VERSION ""

NS_ :

BS_:

BU_: TLM TLM ECU HV TLM TLM HV TLM ECU STEERING_WHEEL HV ECU TLM INVERTER_L HV INVERTER_L TLM ECU ECU INVERTER_L LV ECU HV TLM LV TLM TLM STEERING_WHEEL LV HV LV HV LV HV LV TLM TLM LV HV ECU LV TLM HANDCART HV ECU HV HANDCART HV HV ECU HV ECU HV HV TLM HV CHARGER TLM HV HANDCART HV HANDCART HV HV CHARGER CHARGER ECU LV HANDCART STEERING_WHEEL TLM HANDCART TLM TLM CHARGER HV ECU HANDCART ECU TLM HANDCART HANDCART ECU STEERING_WHEEL HANDCART ECU HV HV ANY LV HV LV ANY ECU ECU ANY LV HV ANY LV ANY HANDCART ECU HV ANY STEERING_WHEEL LV HANDCART CHARGER HANDCART LV LV CHARGER STEERING_WHEEL HANDCART LV STEERING_WHEEL HANDCART CHARGER LV CHARGER ECU TLM LV HANDCART TLM TLM HV CHARGER LV HV LV HANDCART LV TLM TLM CHARGER ECU HV ECU HANDCART LV TLM ECU CHARGER ECU HV HV HANDCART ECU TLM LV HV CHARGER ECU HANDCART LV CHARGER ECU HANDCART TLM LV STEERING_WHEEL LV LV ECU ECU HANDCART LV ECU HV TLM HV HANDCART HANDCART HV HV HANDCART STEERING_WHEEL HANDCART HV TLM TLM ECU HANDCART HANDCART ECU ECU STEERING_WHEEL ECU HV ECU STEERING_WHEEL HANDCART CHARGER ECU TLM HANDCART ECU HANDCART ECU STEERING_WHEEL CHARGER ECU HANDCART STEERING_WHEEL CHARGER ECU HV HANDCART ECU ECU CHARGER STEERING_WHEEL CHARGER ECU HANDCART ECU TLM CHARGER INVERTER_L TLM

BO_ 1818 NLG5_DIAG_TX: 8 NLG5
 SG_ LAD_D_ParamRp : 7|64@0+ (1,0) [0|0] "" Vector__XXX

BO_ 1816 NLG5_DIAG_RX: 8 Control
 SG_ LAD_D_ParamRq : 7|64@0+ (1,0) [0|0] "" Vector__XXX

BO_ 1556 NLG5_ERR: 5 NLG5
 SG_ NLG5_W_SC_M : 32|1@0+ (1,0) [0|0] ""  Control
 SG_ NLG5_W_OD : 33|1@0+ (1,0) [0|0] "" Vector__XXX
 SG_ NLG5_W_CM_NA : 35|1@0+ (1,0) [0|0] "" Vector__XXX
 SG_ NLG5_W_C_VOR : 36|1@0+ (1,0) [0|1] ""  Control
 SG_ NLG5_W_PL_IT : 37|1@0+ (1,0) [0|1] ""  Control
 SG_ NLG5_W_PL_BV : 38|1@0+ (1,0) [0|1] ""  Control
 SG_ NLG5_W_PL_MV : 39|1@0+ (1,0) [0|1] ""  Control
 SG_ NLG5_E_SDT_CT : 26|1@0+ (1,0) [0|1] ""  Control
 SG_ NLG5_E_SDT_AH : 27|1@0+ (1,0) [0|1] ""  Control
 SG_ NLG5_E_SDT_BV : 28|1@0+ (1,0) [0|1] ""  Control
 SG_ NLG5_E_SDT_BT : 29|1@0+ (1,0) [0|1] ""  Control
 SG_ NLG5_E_C_RX : 30|1@0+ (1,0) [0|1] ""  Control
 SG_ NLG5_E_C_TX : 31|1@0+ (1,0) [0|1] ""  Control
 SG_ NLG5_E_C_OFF : 16|1@0+ (1,0) [0|1] ""  Control
 SG_ NLG5_E_C_TO : 17|1@0+ (1,0) [0|1] ""  Control
 SG_ NLG5_E_INIT : 18|1@0+ (1,0) [0|1] ""  Control
 SG_ NLG5_E_WDT : 19|1@0+ (1,0) [0|1] ""  Control
 SG_ NLG5_E_EP_CRC : 20|1@0+ (1,0) [0|1] ""  Control
 SG_ NLG5_E_ES_CRC : 21|1@0+ (1,0) [0|1] ""  Control
 SG_ NLG5_E_NV_CRC : 22|1@0+ (1,0) [0|1] ""  Control
 SG_ NLG5_E_F_CRC : 23|1@0+ (1,0) [0|1] ""  Control
 SG_ NLG5_E_T_EXT3 : 8|1@0+ (1,0) [0|1] ""  Control
 SG_ NLG5_E_T_EXT2 : 9|1@0+ (1,0) [0|1] ""  Control
 SG_ NLG5_E_T_EXT1 : 10|1@0+ (1,0) [0|1] ""  Control
 SG_ NLG5_E_T_TR : 11|1@0+ (1,0) [0|1] ""  Control
 SG_ NLG5_E_T_DIO : 12|1@0+ (1,0) [0|1] ""  Control
 SG_ NLG5_E_T_POW : 13|1@0+ (1,0) [0|1] ""  Control
 SG_ NLG5_E_T_C : 14|1@0+ (1,0) [0|1] ""  Control
 SG_ NLG5_E_B_P : 15|1@0+ (1,0) [0|1] ""  Control
 SG_ NLG5_E_MF : 0|1@0+ (1,0) [0|1] ""  Control
 SG_ NLG5_E_OF : 1|1@0+ (1,0) [0|1] ""  Control
 SG_ NLG5_E_P_MV : 2|1@0+ (1,0) [0|1] ""  Control
 SG_ NLG5_E_P_OM : 3|1@0+ (1,0) [0|1] ""  Control
 SG_ NLG5_E_SC : 4|1@0+ (1,0) [0|1] ""  Control
 SG_ NLG5_E_MOV_I : 5|1@0+ (1,0) [0|1] ""  Control
 SG_ NLG5_E_MOV_II : 6|1@0+ (1,0) [0|1] ""  Control
 SG_ NLG5_E_OOV : 7|1@0+ (1,0) [0|1] ""  Control

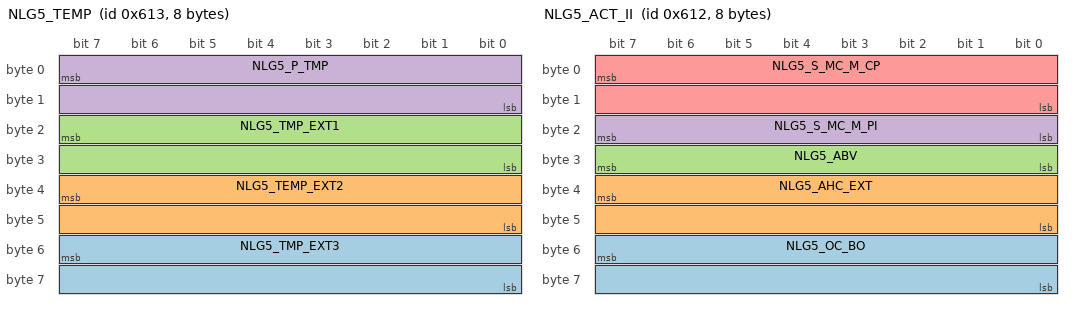
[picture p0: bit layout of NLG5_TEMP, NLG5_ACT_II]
BO_ 1555 NLG5_TEMP: 8 NLG5
 SG_ NLG5_TMP_EXT3 : 55|16@0- (0.1,0) [-40|300] "°C"  Control
 SG_ NLG5_TEMP_EXT2 : 39|16@0- (0.1,0) [-40|300] "°C"  Control
 SG_ NLG5_TMP_EXT1 : 23|16@0- (0.1,0) [-40|300] "°C"  Control
 SG_ NLG5_P_TMP : 7|16@0- (0.1,0) [-40|300] "°C"  Control

BO_ 1554 NLG5_ACT_II: 8 NLG5
 SG_ NLG5_OC_BO : 55|16@0+ (0.01,0) [0|50] "A"  Control
 SG_ NLG5_AHC_EXT : 39|16@0- (0.01,0) [-327.68|327.67] "Ah"  Control
 SG_ NLG5_ABV : 31|8@0+ (0.1,0) [0|25] "V"  Control
 SG_ NLG5_S_MC_M_PI : 23|8@0+ (0.1,0) [0|20] "A"  Control
 SG_ NLG5_S_MC_M_CP : 7|16@0+ (0.1,0) [0|100] "A"  Control

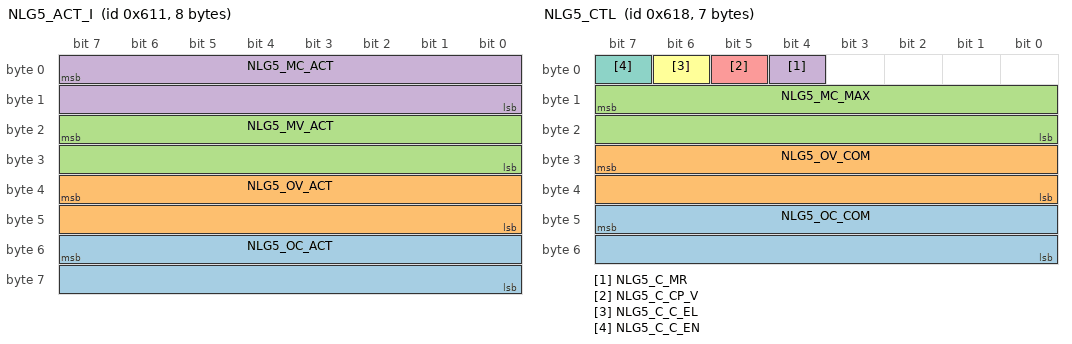
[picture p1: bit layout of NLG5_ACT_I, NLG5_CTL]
BO_ 1553 NLG5_ACT_I: 8 NLG5
 SG_ NLG5_OC_ACT : 55|16@0- (0.01,0) [0|150] "A"  Control
 SG_ NLG5_OV_ACT : 39|16@0+ (0.1,0) [0|1000] "V"  Control
 SG_ NLG5_MV_ACT : 23|16@0+ (0.1,0) [0|500] "V"  Control
 SG_ NLG5_MC_ACT : 7|16@0+ (0.01,0) [0|50] "A"  Control

BO_ 1552 NLG5_ST: 4 NLG5
 SG_ NLG5_S_AAC : 24|1@0+ (1,0) [0|1] ""  Control
 SG_ NLG5_S_L_T_BATT : 16|1@0+ (1,0) [0|1] ""  Control
 SG_ NLG5_S_L_T_TR : 17|1@0+ (1,0) [0|1] ""  Control
 SG_ NLG5_S_L_T_DIO : 18|1@0+ (1,0) [0|1] ""  Control
 SG_ NLG5_S_L_T_POW : 19|1@0+ (1,0) [0|1] ""  Control
 SG_ NLG5_S_L_T_CPRIM : 20|1@0+ (1,0) [0|1] ""  Control
 SG_ NLG5_S_L_MO_MAX : 21|1@0+ (1,0) [0|1] ""  Control
 SG_ NLG5_S_L_OC_MAX : 22|1@0+ (1,0) [0|1] ""  Control
 SG_ NLG5_S_L_MC_MAX : 23|1@0+ (1,0) [0|1] ""  Control
 SG_ NLG5_S_L_PMAX : 8|1@0+ (1,0) [0|1] ""  Control
 SG_ NLG5_S_L_CP : 9|1@0+ (1,0) [0|1] ""  Control
 SG_ NLG5_S_L_PI : 10|1@0+ (1,0) [0|1] ""  Control
 SG_ NLG5_S_L_MC : 11|1@0+ (1,0) [0|1] ""  Control
 SG_ NLG5_S_L_OC : 12|1@0+ (1,0) [0|1] ""  Control
 SG_ NLG5_S_L_OV : 13|1@0+ (1,0) [0|1] ""  Control
 SG_ NLG5_S_BPD_II : 14|1@0+ (1,0) [0|1] ""  Control
 SG_ NLG5_S_BPD_I : 15|1@0+ (1,0) [0|1] ""  Control
 SG_ NLG5_S_CP_DT : 0|1@0+ (1,0) [0|1] ""  Control
 SG_ NLG5_S_UM_II : 1|1@0+ (1,0) [0|1] ""  Control
 SG_ NLG5_S_UM_I : 2|1@0+ (1,0) [0|1] ""  Control
 SG_ NLG5_S_EUM : 3|1@0+ (1,0) [0|1] ""  Control
 SG_ NLG5_S_FAN : 4|1@0+ (1,0) [0|1] ""  Control
 SG_ NLG5_S_WAR : 5|1@0+ (1,0) [0|1] ""  Control
 SG_ NLG5_S_ERR : 6|1@0+ (1,0) [0|1] ""  Control
 SG_ NLG5_S_HE : 7|1@0+ (1,0) [0|1] ""  Control

BO_ 1560 NLG5_CTL: 7 Control
 SG_ NLG5_OC_COM : 47|16@0+ (0.1,0) [0|150] "A"  NLG5
 SG_ NLG5_OV_COM : 31|16@0+ (0.1,0) [0|1000] "V"  NLG5
 SG_ NLG5_MC_MAX : 15|16@0+ (0.1,0) [0|50] "A"  NLG5
 SG_ NLG5_C_MR : 4|1@0+ (1,0) [0|1] ""  NLG5
 SG_ NLG5_C_CP_V : 5|1@0+ (1,0) [0|1] ""  NLG5
 SG_ NLG5_C_C_EL : 6|1@0+ (1,0) [0|1] ""  NLG5
 SG_ NLG5_C_C_EN : 7|1@0+ (1,0) [0|1] ""  NLG5

BO_ 0 HV_JMP_TO_BLT: 1 Vector__XXX
 SG_ cellboard_id : 1|3@1+ (1,0) [0|7] "" Vector__XXX
 SG_ forward : 0|1@1+ (1,0) [0|1] "" Vector__XXX

BO_ 1 HV_FLASH_MAINBOARD_TX: 0 Vector__XXX

BO_ 2 HV_FLASH_MAINBOARD_RX: 0 Vector__XXX

BO_ 4 HV_FLASH_CELLBOARD_0_TX: 0 Vector__XXX

BO_ 5 HV_FLASH_CELLBOARD_0_RX: 0 Vector__XXX

BO_ 6 HV_FLASH_CELLBOARD_1_TX: 0 Vector__XXX

BO_ 7 HV_FLASH_CELLBOARD_1_RX: 0 Vector__XXX

BO_ 8 HV_FLASH_CELLBOARD_2_TX: 0 Vector__XXX

BO_ 9 HV_FLASH_CELLBOARD_2_RX: 0 Vector__XXX

BO_ 10 HV_FLASH_CELLBOARD_3_TX: 0 Vector__XXX

BO_ 11 HV_FLASH_CELLBOARD_3_RX: 0 Vector__XXX

BO_ 12 HV_FLASH_CELLBOARD_4_TX: 0 Vector__XXX

BO_ 13 HV_FLASH_CELLBOARD_4_RX: 0 Vector__XXX

BO_ 14 HV_FLASH_CELLBOARD_5_TX: 0 Vector__XXX

BO_ 15 HV_FLASH_CELLBOARD_5_RX: 0 Vector__XXX

BO_ 16 LV_JMP_TO_BLT: 0 Vector__XXX

BO_ 17 LV_FLASH_TX: 0 Vector__XXX

BO_ 18 LV_FLASH_RX: 0 Vector__XXX

BO_ 19 ECU_JMP_TO_BLT: 0 Vector__XXX

BO_ 20 ECU_FLASH_TX: 0 Vector__XXX

BO_ 21 ECU_FLASH_RX: 0 Vector__XXX

BO_ 22 STEERING_WHEEL_JMP_TO_BLT: 0 Vector__XXX

BO_ 23 STEERING_WHEEL_FLASH_TX: 0 Vector__XXX

BO_ 24 STEERING_WHEEL_FLASH_RX: 0 Vector__XXX

BO_ 700 STEERING_WHEEL_VERSION: 8 Vector__XXX
 SG_ canlib_build_time : 32|32@1+ (1,0) [0|4294967295] "" Vector__XXX
 SG_ component_build_time : 0|32@1+ (1,0) [0|4294967295] "" Vector__XXX

BO_ 701 ECU_VERSION: 8 Vector__XXX
 SG_ canlib_build_time : 32|32@1+ (1,0) [0|4294967295] "" Vector__XXX
 SG_ component_build_time : 0|32@1+ (1,0) [0|4294967295] "" Vector__XXX

BO_ 703 LV_VERSION: 8 Vector__XXX
 SG_ canlib_build_time : 32|32@1+ (1,0) [0|4294967295] "" Vector__XXX
 SG_ component_build_time : 0|32@1+ (1,0) [0|4294967295] "" Vector__XXX

BO_ 704 TLM_VERSION: 8 Vector__XXX
 SG_ canlib_build_time : 32|32@1+ (1,0) [0|4294967295] "" Vector__XXX
 SG_ component_build_time : 0|32@1+ (1,0) [0|4294967295] "" Vector__XXX

BO_ 702 HV_MAINBOARD_VERSION: 8 Vector__XXX
 SG_ canlib_build_time : 32|32@1+ (1,0) [0|4294967295] "" Vector__XXX
 SG_ component_build_time : 0|32@1+ (1,0) [0|4294967295] "" Vector__XXX

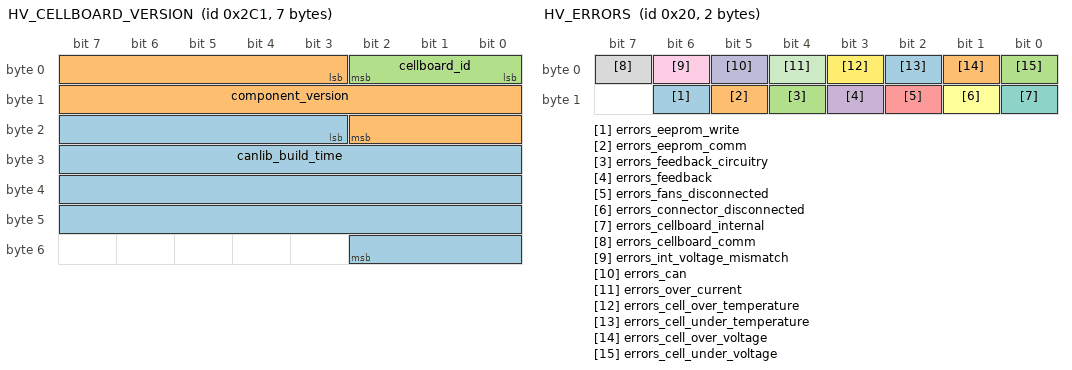
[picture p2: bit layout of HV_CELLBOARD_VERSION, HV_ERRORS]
BO_ 705 HV_CELLBOARD_VERSION: 7 Vector__XXX
 SG_ canlib_build_time : 19|32@1+ (1,0) [0|4294967295] "" Vector__XXX
 SG_ component_version : 3|16@1+ (1,0) [0|65535] "" Vector__XXX
 SG_ cellboard_id : 0|3@1+ (1,0) [0|7] "" Vector__XXX

BO_ 32 HV_ERRORS: 2 Vector__XXX
 SG_ errors_eeprom_write : 14|1@1+ (1,0) [0|1] "" Vector__XXX
 SG_ errors_eeprom_comm : 13|1@1+ (1,0) [0|1] "" Vector__XXX
 SG_ errors_feedback_circuitry : 12|1@1+ (1,0) [0|1] "" Vector__XXX
 SG_ errors_feedback : 11|1@1+ (1,0) [0|1] "" Vector__XXX
 SG_ errors_fans_disconnected : 10|1@1+ (1,0) [0|1] "" Vector__XXX
 SG_ errors_connector_disconnected : 9|1@1+ (1,0) [0|1] "" Vector__XXX
 SG_ errors_cellboard_internal : 8|1@1+ (1,0) [0|1] "" Vector__XXX
 SG_ errors_cellboard_comm : 7|1@1+ (1,0) [0|1] "" Vector__XXX
 SG_ errors_int_voltage_mismatch : 6|1@1+ (1,0) [0|1] "" Vector__XXX
 SG_ errors_can : 5|1@1+ (1,0) [0|1] "" Vector__XXX
 SG_ errors_over_current : 4|1@1+ (1,0) [0|1] "" Vector__XXX
 SG_ errors_cell_over_temperature : 3|1@1+ (1,0) [0|1] "" Vector__XXX
 SG_ errors_cell_under_temperature : 2|1@1+ (1,0) [0|1] "" Vector__XXX
 SG_ errors_cell_over_voltage : 1|1@1+ (1,0) [0|1] "" Vector__XXX
 SG_ errors_cell_under_voltage : 0|1@1+ (1,0) [0|1] "" Vector__XXX

BO_ 512 HV_DEBUG_SIGNALS: 5 Vector__XXX
 SG_ errors_eeprom_write : 34|1@1+ (1,0) [0|1] "" Vector__XXX
 SG_ errors_eeprom_comm : 33|1@1+ (1,0) [0|1] "" Vector__XXX
 SG_ errors_feedback_circuitry : 32|1@1+ (1,0) [0|1] "" Vector__XXX
 SG_ errors_feedback : 31|1@1+ (1,0) [0|1] "" Vector__XXX
 SG_ errors_fans_disconnected : 30|1@1+ (1,0) [0|1] "" Vector__XXX
 SG_ errors_connector_disconnected : 29|1@1+ (1,0) [0|1] "" Vector__XXX
 SG_ errors_cellboard_internal : 28|1@1+ (1,0) [0|1] "" Vector__XXX
 SG_ errors_cellboard_comm : 27|1@1+ (1,0) [0|1] "" Vector__XXX
 SG_ errors_int_voltage_mismatch : 26|1@1+ (1,0) [0|1] "" Vector__XXX
 SG_ errors_can : 25|1@1+ (1,0) [0|1] "" Vector__XXX
 SG_ errors_over_current : 24|1@1+ (1,0) [0|1] "" Vector__XXX
 SG_ errors_cell_over_temperature : 23|1@1+ (1,0) [0|1] "" Vector__XXX
 SG_ errors_cell_under_temperature : 22|1@1+ (1,0) [0|1] "" Vector__XXX
 SG_ errors_cell_over_voltage : 21|1@1+ (1,0) [0|1] "" Vector__XXX
 SG_ errors_cell_under_voltage : 20|1@1+ (1,0) [0|1] "" Vector__XXX
 SG_ feedbacks_sd_imd : 19|1@1+ (1,0) [0|1] "" Vector__XXX
 SG_ feedbacks_sd_bms : 18|1@1+ (1,0) [0|1] "" Vector__XXX
 SG_ feedbacks_sd_in : 17|1@1+ (1,0) [0|1] "" Vector__XXX
 SG_ feedbacks_sd_out : 16|1@1+ (1,0) [0|1] "" Vector__XXX
 SG_ feedbacks_sd_end : 15|1@1+ (1,0) [0|1] "" Vector__XXX
 SG_ feedbacks_check_mux : 14|1@1+ (1,0) [0|1] "" Vector__XXX
 SG_ feedbacks_imd_fault : 13|1@1+ (1,0) [0|1] "" Vector__XXX
 SG_ feedbacks_tsp_over_60v_status : 12|1@1+ (1,0) [0|1] "" Vector__XXX
 SG_ feedbacks_precharge_status : 11|1@1+ (1,0) [0|1] "" Vector__XXX
 SG_ feedbacks_airn_gate : 10|1@1+ (1,0) [0|1] "" Vector__XXX
 SG_ feedbacks_airp_gate : 9|1@1+ (1,0) [0|1] "" Vector__XXX
 SG_ feedbacks_airp_status : 8|1@1+ (1,0) [0|1] "" Vector__XXX
 SG_ feedbacks_airn_status : 7|1@1+ (1,0) [0|1] "" Vector__XXX
 SG_ feedbacks_ts_over_60v_status : 6|1@1+ (1,0) [0|1] "" Vector__XXX
 SG_ feedbacks_tsal_green : 5|1@1+ (1,0) [0|1] "" Vector__XXX
 SG_ feedbacks_ext_latched : 4|1@1+ (1,0) [0|1] "" Vector__XXX
 SG_ feedbacks_bms_cockpit : 3|1@1+ (1,0) [0|1] "" Vector__XXX
 SG_ feedbacks_tsal_green_fault_latched : 2|1@1+ (1,0) [0|1] "" Vector__XXX
 SG_ feedbacks_imd_cockpit : 1|1@1+ (1,0) [0|1] "" Vector__XXX
 SG_ feedbacks_implausibility_detected : 0|1@1+ (1,0) [0|1] "" Vector__XXX

BO_ 1536 HV_FANS_STATUS: 3 Vector__XXX
 SG_ fans_speed : 1|16@1+ (1.5259021896696422e-05,0) [0|1] "" Vector__XXX
 SG_ fans_override : 0|1@1+ (1,0) [0|1] "" Vector__XXX

BO_ 1024 HV_SET_FANS_STATUS: 3 Vector__XXX
 SG_ fans_speed : 1|16@1+ (1.5259021896696422e-05,0) [0|1] "" Vector__XXX
 SG_ fans_override : 0|1@1+ (1,0) [0|1] "" Vector__XXX

BO_ 520 HV_FEEDBACK_STATUS: 5 Vector__XXX
 SG_ feedback_sd_imd : 38|2@1+ (1,0) [0|3] "" Vector__XXX
 SG_ feedback_sd_bms : 36|2@1+ (1,0) [0|3] "" Vector__XXX
 SG_ feedback_sd_in : 34|2@1+ (1,0) [0|3] "" Vector__XXX
 SG_ feedback_sd_out : 32|2@1+ (1,0) [0|3] "" Vector__XXX
 SG_ feedback_sd_end : 30|2@1+ (1,0) [0|3] "" Vector__XXX
 SG_ feedback_check_mux : 28|2@1+ (1,0) [0|3] "" Vector__XXX
 SG_ feedback_imd_fault : 26|2@1+ (1,0) [0|3] "" Vector__XXX
 SG_ feedback_tsp_over_60v_status : 24|2@1+ (1,0) [0|3] "" Vector__XXX
 SG_ feedback_precharge_status : 22|2@1+ (1,0) [0|3] "" Vector__XXX
 SG_ feedback_airn_gate : 20|2@1+ (1,0) [0|3] "" Vector__XXX
 SG_ feedback_airp_gate : 18|2@1+ (1,0) [0|3] "" Vector__XXX
 SG_ feedback_airp_status : 16|2@1+ (1,0) [0|3] "" Vector__XXX
 SG_ feedback_airn_status : 14|2@1+ (1,0) [0|3] "" Vector__XXX
 SG_ feedback_ts_over_60v_status : 12|2@1+ (1,0) [0|3] "" Vector__XXX
 SG_ feedback_tsal_green : 10|2@1+ (1,0) [0|3] "" Vector__XXX
 SG_ feedback_ext_latched : 8|2@1+ (1,0) [0|3] "" Vector__XXX
 SG_ feedback_bms_cockpit : 6|2@1+ (1,0) [0|3] "" Vector__XXX
 SG_ feedback_tsal_green_fault_latched : 4|2@1+ (1,0) [0|3] "" Vector__XXX
 SG_ feedback_imd_cockpit : 2|2@1+ (1,0) [0|3] "" Vector__XXX
 SG_ feedback_implausibility_detected : 0|2@1+ (1,0) [0|3] "" Vector__XXX

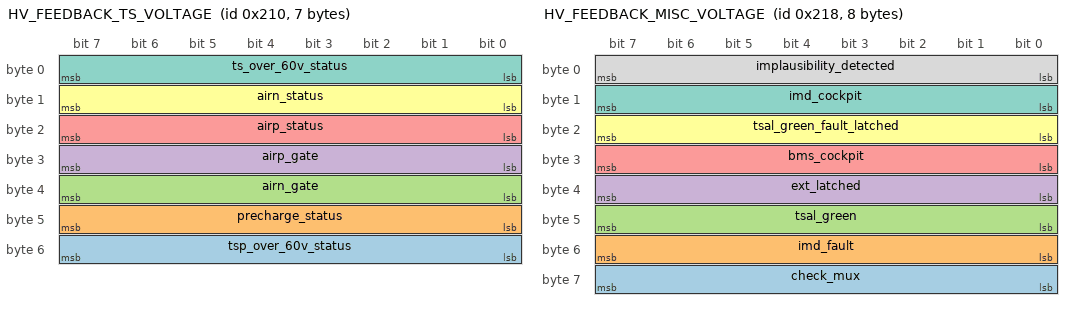
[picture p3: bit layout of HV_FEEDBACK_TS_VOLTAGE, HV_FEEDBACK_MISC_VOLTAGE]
BO_ 528 HV_FEEDBACK_TS_VOLTAGE: 7 Vector__XXX
 SG_ tsp_over_60v_status : 48|8@1+ (0.012941176470588235,0) [0|3.3] "" Vector__XXX
 SG_ precharge_status : 40|8@1+ (0.012941176470588235,0) [0|3.3] "" Vector__XXX
 SG_ airn_gate : 32|8@1+ (0.012941176470588235,0) [0|3.3] "" Vector__XXX
 SG_ airp_gate : 24|8@1+ (0.012941176470588235,0) [0|3.3] "" Vector__XXX
 SG_ airp_status : 16|8@1+ (0.012941176470588235,0) [0|3.3] "" Vector__XXX
 SG_ airn_status : 8|8@1+ (0.012941176470588235,0) [0|3.3] "" Vector__XXX
 SG_ ts_over_60v_status : 0|8@1+ (0.012941176470588235,0) [0|3.3] "" Vector__XXX

BO_ 536 HV_FEEDBACK_MISC_VOLTAGE: 8 Vector__XXX
 SG_ check_mux : 56|8@1+ (0.012941176470588235,0) [0|3.3] "" Vector__XXX
 SG_ imd_fault : 48|8@1+ (0.012941176470588235,0) [0|3.3] "" Vector__XXX
 SG_ tsal_green : 40|8@1+ (0.012941176470588235,0) [0|3.3] "" Vector__XXX
 SG_ ext_latched : 32|8@1+ (0.012941176470588235,0) [0|3.3] "" Vector__XXX
 SG_ bms_cockpit : 24|8@1+ (0.012941176470588235,0) [0|3.3] "" Vector__XXX
 SG_ tsal_green_fault_latched : 16|8@1+ (0.012941176470588235,0) [0|3.3] "" Vector__XXX
 SG_ imd_cockpit : 8|8@1+ (0.012941176470588235,0) [0|3.3] "" Vector__XXX
 SG_ implausibility_detected : 0|8@1+ (0.012941176470588235,0) [0|3.3] "" Vector__XXX

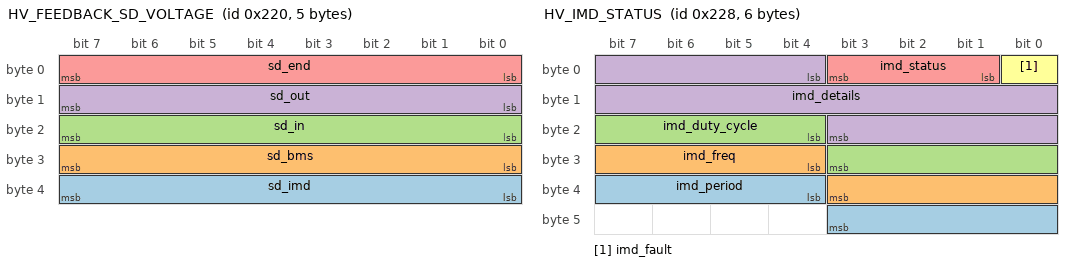
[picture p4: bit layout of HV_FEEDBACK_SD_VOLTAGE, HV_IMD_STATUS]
BO_ 544 HV_FEEDBACK_SD_VOLTAGE: 5 Vector__XXX
 SG_ sd_imd : 32|8@1+ (0.012941176470588235,0) [0|3.3] "" Vector__XXX
 SG_ sd_bms : 24|8@1+ (0.012941176470588235,0) [0|3.3] "" Vector__XXX
 SG_ sd_in : 16|8@1+ (0.012941176470588235,0) [0|3.3] "" Vector__XXX
 SG_ sd_out : 8|8@1+ (0.012941176470588235,0) [0|3.3] "" Vector__XXX
 SG_ sd_end : 0|8@1+ (0.012941176470588235,0) [0|3.3] "" Vector__XXX

BO_ 552 HV_IMD_STATUS: 6 Vector__XXX
 SG_ imd_period : 36|8@1+ (1,0) [0|255] "" Vector__XXX
 SG_ imd_freq : 28|8@1+ (1,0) [0|255] "" Vector__XXX
 SG_ imd_duty_cycle : 20|8@1+ (1,0) [0|255] "" Vector__XXX
 SG_ imd_details : 4|16@1+ (1,0) [0|65535] "" Vector__XXX
 SG_ imd_status : 1|3@1+ (1,0) [0|7] "" Vector__XXX
 SG_ imd_fault : 0|1@1+ (1,0) [0|1] "" Vector__XXX

BO_ 560 HV_STATUS: 1 Vector__XXX
 SG_ status : 0|3@1+ (1,0) [0|7] "" Vector__XXX

BO_ 40 HV_SET_STATUS_ECU: 1 Vector__XXX
 SG_ hv_status_set : 0|1@1+ (1,0) [0|1] "" Vector__XXX

BO_ 48 HV_SET_STATUS_HANDCART: 1 Vector__XXX
 SG_ hv_status_set : 0|1@1+ (1,0) [0|1] "" Vector__XXX

BO_ 1544 HV_BALANCING_STATUS: 4 Vector__XXX
 SG_ balancing_cells_cell17 : 30|1@1+ (1,0) [0|1] "" Vector__XXX
 SG_ balancing_cells_cell16 : 29|1@1+ (1,0) [0|1] "" Vector__XXX
 SG_ balancing_cells_cell15 : 28|1@1+ (1,0) [0|1] "" Vector__XXX
 SG_ balancing_cells_cell14 : 27|1@1+ (1,0) [0|1] "" Vector__XXX
 SG_ balancing_cells_cell13 : 26|1@1+ (1,0) [0|1] "" Vector__XXX
 SG_ balancing_cells_cell12 : 25|1@1+ (1,0) [0|1] "" Vector__XXX
 SG_ balancing_cells_cell11 : 24|1@1+ (1,0) [0|1] "" Vector__XXX
 SG_ balancing_cells_cell10 : 23|1@1+ (1,0) [0|1] "" Vector__XXX
 SG_ balancing_cells_cell9 : 22|1@1+ (1,0) [0|1] "" Vector__XXX
 SG_ balancing_cells_cell8 : 21|1@1+ (1,0) [0|1] "" Vector__XXX
 SG_ balancing_cells_cell7 : 20|1@1+ (1,0) [0|1] "" Vector__XXX
 SG_ balancing_cells_cell6 : 19|1@1+ (1,0) [0|1] "" Vector__XXX
 SG_ balancing_cells_cell5 : 18|1@1+ (1,0) [0|1] "" Vector__XXX
 SG_ balancing_cells_cell4 : 17|1@1+ (1,0) [0|1] "" Vector__XXX
 SG_ balancing_cells_cell3 : 16|1@1+ (1,0) [0|1] "" Vector__XXX
 SG_ balancing_cells_cell2 : 15|1@1+ (1,0) [0|1] "" Vector__XXX
 SG_ balancing_cells_cell1 : 14|1@1+ (1,0) [0|1] "" Vector__XXX
 SG_ balancing_cells_cell0 : 13|1@1+ (1,0) [0|1] "" Vector__XXX
 SG_ errors_open_wire : 12|1@1+ (1,0) [0|1] "" Vector__XXX
 SG_ errors_temp_comm_5 : 11|1@1+ (1,0) [0|1] "" Vector__XXX
 SG_ errors_temp_comm_4 : 10|1@1+ (1,0) [0|1] "" Vector__XXX
 SG_ errors_temp_comm_3 : 9|1@1+ (1,0) [0|1] "" Vector__XXX
 SG_ errors_temp_comm_2 : 8|1@1+ (1,0) [0|1] "" Vector__XXX
 SG_ errors_temp_comm_1 : 7|1@1+ (1,0) [0|1] "" Vector__XXX
 SG_ errors_temp_comm_0 : 6|1@1+ (1,0) [0|1] "" Vector__XXX
 SG_ errors_ltc_comm : 5|1@1+ (1,0) [0|1] "" Vector__XXX
 SG_ errors_can_comm : 4|1@1+ (1,0) [0|1] "" Vector__XXX
 SG_ balancing_status : 3|1@1+ (1,0) [0|1] "" Vector__XXX
 SG_ cellboard_id : 0|3@1+ (1,0) [0|7] "" Vector__XXX

BO_ 1032 HV_SET_BALANCING_STATUS_HANDCART: 2 Vector__XXX
 SG_ balancing_threshold : 1|8@1+ (1,5) [5|200] "" Vector__XXX
 SG_ set_balancing_status : 0|1@1+ (1,0) [0|1] "" Vector__XXX

BO_ 1040 HV_SET_BALANCING_STATUS_STEERING_WHEEL: 2 Vector__XXX
 SG_ balancing_threshold : 1|8@1+ (1,5) [5|200] "" Vector__XXX
 SG_ set_balancing_status : 0|1@1+ (1,0) [0|1] "" Vector__XXX

BO_ 568 LV_STATUS: 1 Vector__XXX
 SG_ status : 0|3@1+ (1,0) [0|7] "" Vector__XXX

BO_ 1568 LV_CHARGING_STATUS: 1 Vector__XXX
 SG_ status : 0|1@1+ (1,0) [0|1] "" Vector__XXX

BO_ 1576 LV_COOLING_AGGRESSIVENESS: 1 Vector__XXX
 SG_ status : 0|2@1+ (1,0) [0|3] "" Vector__XXX

BO_ 1048 LV_SET_COOLING_AGGRESSIVENESS: 1 Vector__XXX
 SG_ status : 0|2@1+ (1,0) [0|3] "" Vector__XXX

BO_ 1584 LV_RADIATOR_SPEED: 2 Vector__XXX
 SG_ radiator_speed : 2|8@1+ (0.007874015748031496,0) [0|1] "" Vector__XXX
 SG_ status : 0|2@1+ (1,0) [0|3] "" Vector__XXX

BO_ 1592 LV_PUMPS_SPEED: 2 Vector__XXX
 SG_ pumps_speed : 2|8@1+ (0.007874015748031496,0) [0|1] "" Vector__XXX
 SG_ status : 0|2@1+ (1,0) [0|3] "" Vector__XXX

BO_ 1056 LV_SET_RADIATOR_SPEED: 2 Vector__XXX
 SG_ radiator_speed : 2|8@1+ (0.007874015748031496,0) [0|1] "" Vector__XXX
 SG_ status : 0|2@1+ (1,0) [0|3] "" Vector__XXX

BO_ 1064 LV_SET_PUMPS_SPEED: 2 Vector__XXX
 SG_ pumps_speed : 2|8@1+ (0.007874015748031496,0) [0|1] "" Vector__XXX
 SG_ status : 0|2@1+ (1,0) [0|3] "" Vector__XXX

BO_ 576 LV_ERRORS: 3 Vector__XXX
 SG_ health_signals_sign_battery_current : 22|1@1+ (1,0) [0|1] "" Vector__XXX
 SG_ health_signals_battery_current : 21|1@1+ (1,0) [0|1] "" Vector__XXX
 SG_ health_signals_charger_current : 20|1@1+ (1,0) [0|1] "" Vector__XXX
 SG_ health_signals_battery_voltage_out : 19|1@1+ (1,0) [0|1] "" Vector__XXX
 SG_ health_signals_relay_out : 18|1@1+ (1,0) [0|1] "" Vector__XXX
 SG_ health_signals_lvms_out : 17|1@1+ (1,0) [0|1] "" Vector__XXX
 SG_ errors_mux : 16|1@1+ (1,0) [0|1] "" Vector__XXX
 SG_ errors_adc_init : 15|1@1+ (1,0) [0|1] "" Vector__XXX
 SG_ errors_pump : 14|1@1+ (1,0) [0|1] "" Vector__XXX
 SG_ errors_fan : 13|1@1+ (1,0) [0|1] "" Vector__XXX
 SG_ errors_radiator : 12|1@1+ (1,0) [0|1] "" Vector__XXX
 SG_ errors_mcp23017 : 11|1@1+ (1,0) [0|1] "" Vector__XXX
 SG_ errors_voltages_not_ready : 10|1@1+ (1,0) [0|1] "" Vector__XXX
 SG_ errors_bms_monitor : 9|1@1+ (1,0) [0|1] "" Vector__XXX
 SG_ errors_relay : 8|1@1+ (1,0) [0|1] "" Vector__XXX
 SG_ errors_cell_over_temperature : 7|1@1+ (1,0) [0|1] "" Vector__XXX
 SG_ errors_cell_under_temperature : 6|1@1+ (1,0) [0|1] "" Vector__XXX
 SG_ errors_over_current : 5|1@1+ (1,0) [0|1] "" Vector__XXX
 SG_ errors_spi : 4|1@1+ (1,0) [0|1] "" Vector__XXX
 SG_ errors_can : 3|1@1+ (1,0) [0|1] "" Vector__XXX
 SG_ errors_battery_open_wire : 2|1@1+ (1,0) [0|1] "" Vector__XXX
 SG_ errors_cell_overvoltage : 1|1@1+ (1,0) [0|1] "" Vector__XXX
 SG_ errors_cell_undervoltage : 0|1@1+ (1,0) [0|1] "" Vector__XXX

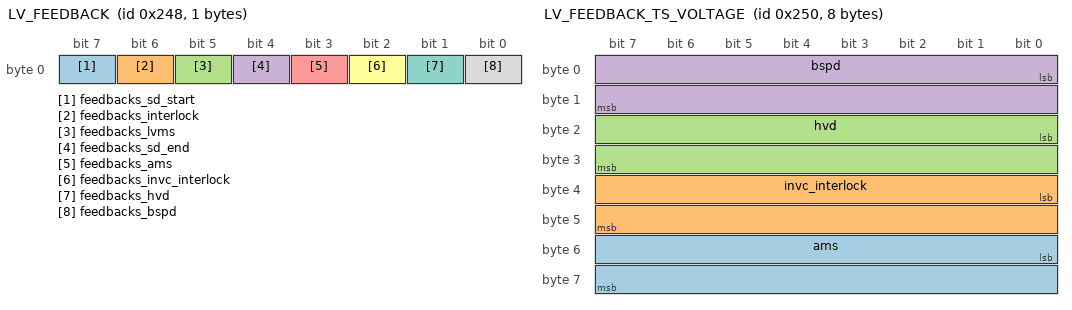
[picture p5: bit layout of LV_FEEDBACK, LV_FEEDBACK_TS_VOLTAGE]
BO_ 584 LV_FEEDBACK: 1 Vector__XXX
 SG_ feedbacks_sd_start : 7|1@1+ (1,0) [0|1] "" Vector__XXX
 SG_ feedbacks_interlock : 6|1@1+ (1,0) [0|1] "" Vector__XXX
 SG_ feedbacks_lvms : 5|1@1+ (1,0) [0|1] "" Vector__XXX
 SG_ feedbacks_sd_end : 4|1@1+ (1,0) [0|1] "" Vector__XXX
 SG_ feedbacks_ams : 3|1@1+ (1,0) [0|1] "" Vector__XXX
 SG_ feedbacks_invc_interlock : 2|1@1+ (1,0) [0|1] "" Vector__XXX
 SG_ feedbacks_hvd : 1|1@1+ (1,0) [0|1] "" Vector__XXX
 SG_ feedbacks_bspd : 0|1@1+ (1,0) [0|1] "" Vector__XXX

BO_ 592 LV_FEEDBACK_TS_VOLTAGE: 8 Vector__XXX
 SG_ ams : 48|16@1+ (0.003418803418803419,0) [0|14] "" Vector__XXX
 SG_ invc_interlock : 32|16@1+ (0.003418803418803419,0) [0|14] "" Vector__XXX
 SG_ hvd : 16|16@1+ (0.003418803418803419,0) [0|14] "" Vector__XXX
 SG_ bspd : 0|16@1+ (0.003418803418803419,0) [0|14] "" Vector__XXX

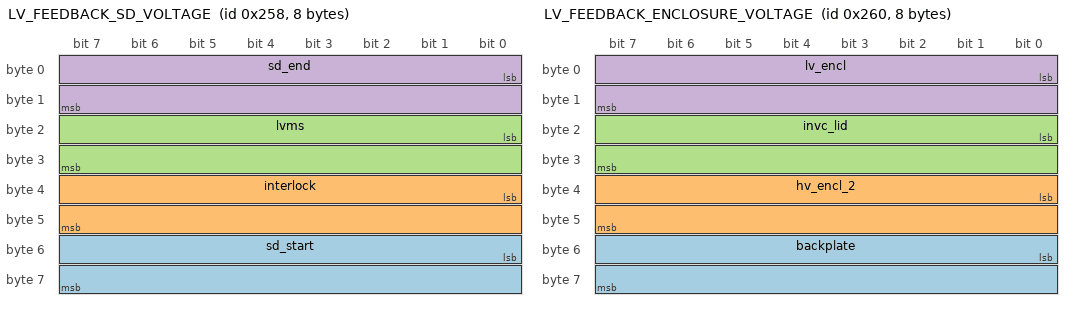
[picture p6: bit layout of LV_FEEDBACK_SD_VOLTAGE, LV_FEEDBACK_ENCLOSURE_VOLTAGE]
BO_ 600 LV_FEEDBACK_SD_VOLTAGE: 8 Vector__XXX
 SG_ sd_start : 48|16@1+ (0.003418803418803419,0) [0|14] "" Vector__XXX
 SG_ interlock : 32|16@1+ (0.003418803418803419,0) [0|14] "" Vector__XXX
 SG_ lvms : 16|16@1+ (0.003418803418803419,0) [0|14] "" Vector__XXX
 SG_ sd_end : 0|16@1+ (0.003418803418803419,0) [0|14] "" Vector__XXX

BO_ 608 LV_FEEDBACK_ENCLOSURE_VOLTAGE: 8 Vector__XXX
 SG_ backplate : 48|16@1+ (0.003418803418803419,0) [0|14] "" Vector__XXX
 SG_ hv_encl_2 : 32|16@1+ (0.003418803418803419,0) [0|14] "" Vector__XXX
 SG_ invc_lid : 16|16@1+ (0.003418803418803419,0) [0|14] "" Vector__XXX
 SG_ lv_encl : 0|16@1+ (0.003418803418803419,0) [0|14] "" Vector__XXX

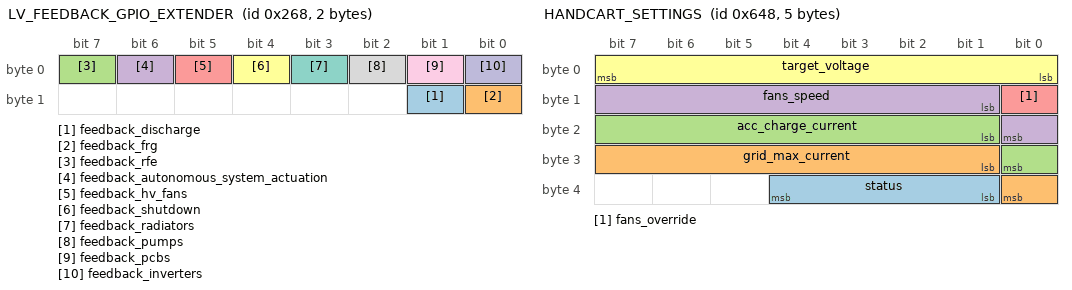
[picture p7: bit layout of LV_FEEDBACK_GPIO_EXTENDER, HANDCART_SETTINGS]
BO_ 616 LV_FEEDBACK_GPIO_EXTENDER: 2 Vector__XXX
 SG_ feedback_discharge : 9|1@1+ (1,0) [0|1] "" Vector__XXX
 SG_ feedback_frg : 8|1@1+ (1,0) [0|1] "" Vector__XXX
 SG_ feedback_rfe : 7|1@1+ (1,0) [0|1] "" Vector__XXX
 SG_ feedback_autonomous_system_actuation : 6|1@1+ (1,0) [0|1] "" Vector__XXX
 SG_ feedback_hv_fans : 5|1@1+ (1,0) [0|1] "" Vector__XXX
 SG_ feedback_shutdown : 4|1@1+ (1,0) [0|1] "" Vector__XXX
 SG_ feedback_radiators : 3|1@1+ (1,0) [0|1] "" Vector__XXX
 SG_ feedback_pumps : 2|1@1+ (1,0) [0|1] "" Vector__XXX
 SG_ feedback_pcbs : 1|1@1+ (1,0) [0|1] "" Vector__XXX
 SG_ feedback_inverters : 0|1@1+ (1,0) [0|1] "" Vector__XXX

BO_ 56 LV_CAN_FLASH_REQ_TLM: 0 Vector__XXX

BO_ 64 LV_CAN_FLASH_REQ_STEERING_WHEEL: 0 Vector__XXX

BO_ 72 LV_CAN_FLASH_ACK: 0 Vector__XXX

BO_ 624 LV_INVERTER_CONNECTION_STATUS: 1 Vector__XXX
 SG_ status : 0|1@1+ (1,0) [0|1] "" Vector__XXX

BO_ 80 LV_SET_INVERTER_CONNECTION_STATUS: 1 Vector__XXX
 SG_ status : 0|1@1+ (1,0) [0|1] "" Vector__XXX

BO_ 1600 TLM_STATUS: 1 Vector__XXX
 SG_ status : 0|1@1+ (1,0) [0|1] "" Vector__XXX

BO_ 1072 TLM_SET_STATUS: 1 Vector__XXX
 SG_ status : 0|1@1+ (1,0) [0|1] "" Vector__XXX

BO_ 632 HANDCART_STATUS: 1 Vector__XXX
 SG_ connected : 0|1@1+ (1,0) [0|1] "" Vector__XXX

BO_ 1608 HANDCART_SETTINGS: 5 Vector__XXX
 SG_ status : 33|4@1+ (1,0) [0|15] "" Vector__XXX
 SG_ grid_max_current : 25|8@1+ (0.058823529411764705,1) [1|16] "" Vector__XXX
 SG_ acc_charge_current : 17|8@1+ (0.058823529411764705,1) [1|16] "" Vector__XXX
 SG_ fans_speed : 9|8@1+ (0.00392156862745098,0) [0|1] "" Vector__XXX
 SG_ fans_override : 8|1@1+ (1,0) [0|1] "" Vector__XXX
 SG_ target_voltage : 0|8@1+ (0.6039215686274509,300) [300|454] "" Vector__XXX

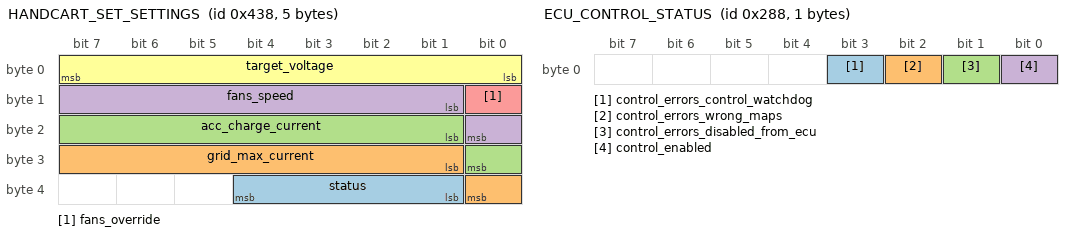
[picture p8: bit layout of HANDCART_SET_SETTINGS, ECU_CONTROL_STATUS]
BO_ 1080 HANDCART_SET_SETTINGS: 5 Vector__XXX
 SG_ status : 33|4@1+ (1,0) [0|15] "" Vector__XXX
 SG_ grid_max_current : 25|8@1+ (0.058823529411764705,1) [1|16] "" Vector__XXX
 SG_ acc_charge_current : 17|8@1+ (0.058823529411764705,1) [1|16] "" Vector__XXX
 SG_ fans_speed : 9|8@1+ (0.00392156862745098,0) [0|1] "" Vector__XXX
 SG_ fans_override : 8|1@1+ (1,0) [0|1] "" Vector__XXX
 SG_ target_voltage : 0|8@1+ (0.6039215686274509,300) [300|454] "" Vector__XXX

BO_ 640 ECU_STATUS: 1 Vector__XXX
 SG_ status : 0|4@1+ (1,0) [0|15] "" Vector__XXX

BO_ 88 ECU_SET_STATUS: 1 Vector__XXX
 SG_ status : 0|2@1+ (1,0) [0|3] "" Vector__XXX

BO_ 1088 ECU_INVERTER_STATUS: 1 Vector__XXX
 SG_ rr : 2|2@1+ (1,0) [0|3] "" Vector__XXX
 SG_ rl : 0|2@1+ (1,0) [0|3] "" Vector__XXX

BO_ 648 ECU_CONTROL_STATUS: 1 Vector__XXX
 SG_ control_errors_control_watchdog : 3|1@1+ (1,0) [0|1] "" Vector__XXX
 SG_ control_errors_wrong_maps : 2|1@1+ (1,0) [0|1] "" Vector__XXX
 SG_ control_errors_disabled_from_ecu : 1|1@1+ (1,0) [0|1] "" Vector__XXX
 SG_ control_enabled : 0|1@1+ (1,0) [0|1] "" Vector__XXX

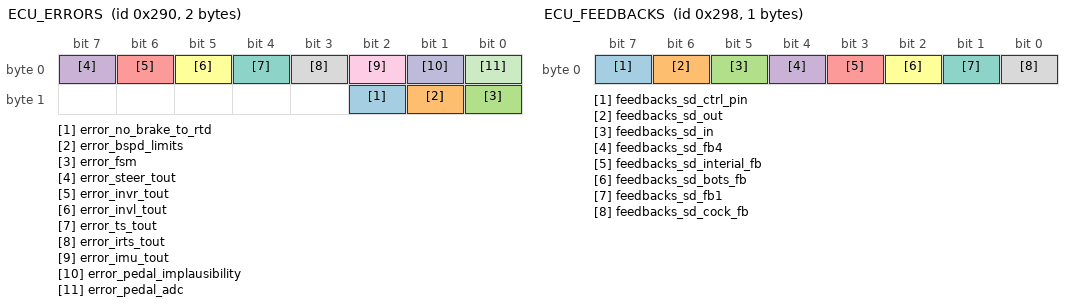
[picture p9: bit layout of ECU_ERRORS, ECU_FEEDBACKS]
BO_ 656 ECU_ERRORS: 2 Vector__XXX
 SG_ error_no_brake_to_rtd : 10|1@1+ (1,0) [0|1] "" Vector__XXX
 SG_ error_bspd_limits : 9|1@1+ (1,0) [0|1] "" Vector__XXX
 SG_ error_fsm : 8|1@1+ (1,0) [0|1] "" Vector__XXX
 SG_ error_steer_tout : 7|1@1+ (1,0) [0|1] "" Vector__XXX
 SG_ error_invr_tout : 6|1@1+ (1,0) [0|1] "" Vector__XXX
 SG_ error_invl_tout : 5|1@1+ (1,0) [0|1] "" Vector__XXX
 SG_ error_ts_tout : 4|1@1+ (1,0) [0|1] "" Vector__XXX
 SG_ error_irts_tout : 3|1@1+ (1,0) [0|1] "" Vector__XXX
 SG_ error_imu_tout : 2|1@1+ (1,0) [0|1] "" Vector__XXX
 SG_ error_pedal_implausibility : 1|1@1+ (1,0) [0|1] "" Vector__XXX
 SG_ error_pedal_adc : 0|1@1+ (1,0) [0|1] "" Vector__XXX

BO_ 664 ECU_FEEDBACKS: 1 Vector__XXX
 SG_ feedbacks_sd_ctrl_pin : 7|1@1+ (1,0) [0|1] "" Vector__XXX
 SG_ feedbacks_sd_out : 6|1@1+ (1,0) [0|1] "" Vector__XXX
 SG_ feedbacks_sd_in : 5|1@1+ (1,0) [0|1] "" Vector__XXX
 SG_ feedbacks_sd_fb4 : 4|1@1+ (1,0) [0|1] "" Vector__XXX
 SG_ feedbacks_sd_interial_fb : 3|1@1+ (1,0) [0|1] "" Vector__XXX
 SG_ feedbacks_sd_bots_fb : 2|1@1+ (1,0) [0|1] "" Vector__XXX
 SG_ feedbacks_sd_fb1 : 1|1@1+ (1,0) [0|1] "" Vector__XXX
 SG_ feedbacks_sd_cock_fb : 0|1@1+ (1,0) [0|1] "" Vector__XXX

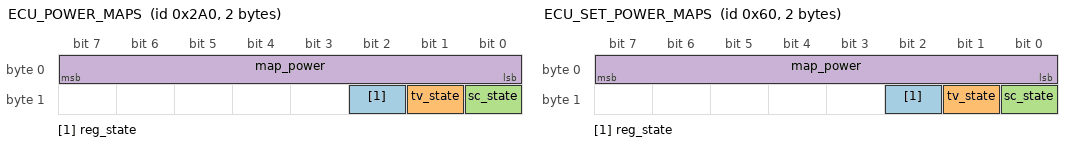
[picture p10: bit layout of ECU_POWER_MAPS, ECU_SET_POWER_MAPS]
BO_ 672 ECU_POWER_MAPS: 2 Vector__XXX
 SG_ reg_state : 10|1@1+ (1,0) [0|1] "" Vector__XXX
 SG_ tv_state : 9|1@1+ (1,0) [0|1] "" Vector__XXX
 SG_ sc_state : 8|1@1+ (1,0) [0|1] "" Vector__XXX
 SG_ map_power : 0|8@1+ (0.01,-0.5) [-0.5|1] "" Vector__XXX

BO_ 96 ECU_SET_POWER_MAPS: 2 Vector__XXX
 SG_ reg_state : 10|1@1+ (1,0) [0|1] "" Vector__XXX
 SG_ tv_state : 9|1@1+ (1,0) [0|1] "" Vector__XXX
 SG_ sc_state : 8|1@1+ (1,0) [0|1] "" Vector__XXX
 SG_ map_power : 0|8@1+ (0.01,-0.5) [-0.5|1] "" Vector__XXX

BO_ 1616 ECU_PTT_STATUS: 1 Vector__XXX
 SG_ status : 0|1@1+ (1,0) [0|1] "" Vector__XXX

BO_ 1096 ECU_SET_PTT_STATUS: 1 Vector__XXX
 SG_ status : 0|1@1+ (1,0) [0|1] "" Vector__XXX

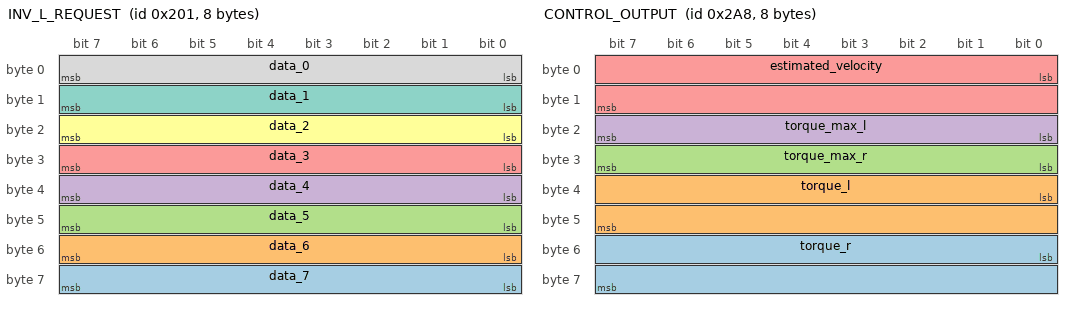
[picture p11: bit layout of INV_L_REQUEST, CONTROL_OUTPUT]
BO_ 513 INV_L_REQUEST: 8 Vector__XXX
 SG_ data_7 : 56|8@1+ (1,0) [0|255] "" Vector__XXX
 SG_ data_6 : 48|8@1+ (1,0) [0|255] "" Vector__XXX
 SG_ data_5 : 40|8@1+ (1,0) [0|255] "" Vector__XXX
 SG_ data_4 : 32|8@1+ (1,0) [0|255] "" Vector__XXX
 SG_ data_3 : 24|8@1+ (1,0) [0|255] "" Vector__XXX
 SG_ data_2 : 16|8@1+ (1,0) [0|255] "" Vector__XXX
 SG_ data_1 : 8|8@1+ (1,0) [0|255] "" Vector__XXX
 SG_ data_0 : 0|8@1+ (1,0) [0|255] "" Vector__XXX

BO_ 680 CONTROL_OUTPUT: 8 Vector__XXX
 SG_ torque_r : 48|16@1+ (0.0030518043793392844,-100) [-100|100] "" Vector__XXX
 SG_ torque_l : 32|16@1+ (0.0030518043793392844,-100) [-100|100] "" Vector__XXX
 SG_ torque_max_r : 24|8@1+ (0.7843137254901961,-100) [-100|100] "" Vector__XXX
 SG_ torque_max_l : 16|8@1+ (0.7843137254901961,-100) [-100|100] "" Vector__XXX
 SG_ estimated_velocity : 0|16@1+ (0.000686655985351339,-10) [-10|35] "" Vector__XXX

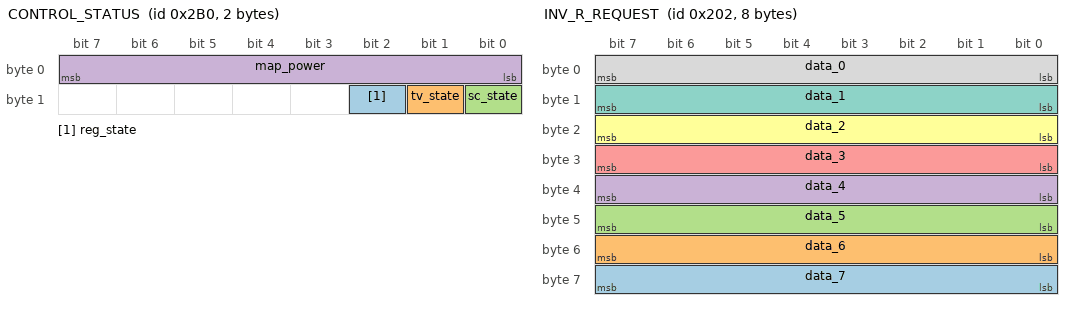
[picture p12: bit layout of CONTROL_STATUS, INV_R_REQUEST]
BO_ 688 CONTROL_STATUS: 2 Vector__XXX
 SG_ reg_state : 10|1@1+ (1,0) [0|1] "" Vector__XXX
 SG_ tv_state : 9|1@1+ (1,0) [0|1] "" Vector__XXX
 SG_ sc_state : 8|1@1+ (1,0) [0|1] "" Vector__XXX
 SG_ map_power : 0|8@1+ (0.01,-0.5) [-0.5|1] "" Vector__XXX

BO_ 514 INV_R_REQUEST: 8 Vector__XXX
 SG_ data_7 : 56|8@1+ (1,0) [0|255] "" Vector__XXX
 SG_ data_6 : 48|8@1+ (1,0) [0|255] "" Vector__XXX
 SG_ data_5 : 40|8@1+ (1,0) [0|255] "" Vector__XXX
 SG_ data_4 : 32|8@1+ (1,0) [0|255] "" Vector__XXX
 SG_ data_3 : 24|8@1+ (1,0) [0|255] "" Vector__XXX
 SG_ data_2 : 16|8@1+ (1,0) [0|255] "" Vector__XXX
 SG_ data_1 : 8|8@1+ (1,0) [0|255] "" Vector__XXX
 SG_ data_0 : 0|8@1+ (1,0) [0|255] "" Vector__XXX

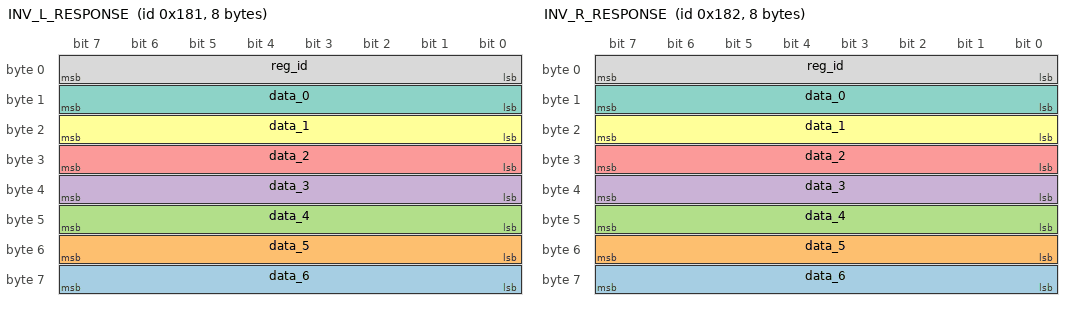
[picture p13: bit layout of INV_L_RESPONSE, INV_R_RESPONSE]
BO_ 385 INV_L_RESPONSE: 8 Vector__XXX
 SG_ data_6 : 56|8@1+ (1,0) [0|255] "" Vector__XXX
 SG_ data_5 : 48|8@1+ (1,0) [0|255] "" Vector__XXX
 SG_ data_4 : 40|8@1+ (1,0) [0|255] "" Vector__XXX
 SG_ data_3 : 32|8@1+ (1,0) [0|255] "" Vector__XXX
 SG_ data_2 : 24|8@1+ (1,0) [0|255] "" Vector__XXX
 SG_ data_1 : 16|8@1+ (1,0) [0|255] "" Vector__XXX
 SG_ data_0 : 8|8@1+ (1,0) [0|255] "" Vector__XXX
 SG_ reg_id : 0|8@1+ (1,0) [0|255] "" Vector__XXX

BO_ 386 INV_R_RESPONSE: 8 Vector__XXX
 SG_ data_6 : 56|8@1+ (1,0) [0|255] "" Vector__XXX
 SG_ data_5 : 48|8@1+ (1,0) [0|255] "" Vector__XXX
 SG_ data_4 : 40|8@1+ (1,0) [0|255] "" Vector__XXX
 SG_ data_3 : 32|8@1+ (1,0) [0|255] "" Vector__XXX
 SG_ data_2 : 24|8@1+ (1,0) [0|255] "" Vector__XXX
 SG_ data_1 : 16|8@1+ (1,0) [0|255] "" Vector__XXX
 SG_ data_0 : 8|8@1+ (1,0) [0|255] "" Vector__XXX
 SG_ reg_id : 0|8@1+ (1,0) [0|255] "" Vector__XXX

BO_ 1624 LV_CURRENT_BATTERY: 2 Vector__XXX
 SG_ lv_current : 0|16@1+ (0.07827788649706457,-20) [-20|20] "" Vector__XXX

BO_ 1632 LV_CURRENT_CHARGER: 2 Vector__XXX
 SG_ charger_current : 0|16@1+ (0.07827788649706457,-20) [-20|20] "" Vector__XXX

BO_ 1640 LV_TOTAL_VOLTAGE: 4 Vector__XXX
 SG_ total : 0|32@1+ (9.918250725748923e-05,0) [0|26] "" Vector__XXX

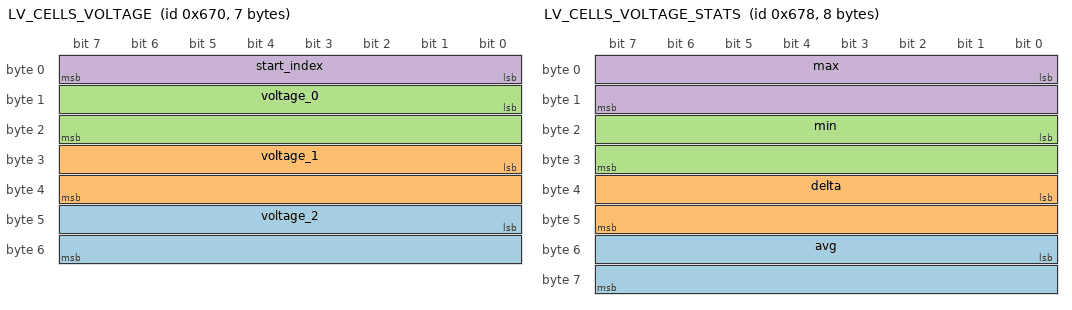
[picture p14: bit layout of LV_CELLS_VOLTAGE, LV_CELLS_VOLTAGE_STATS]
BO_ 1648 LV_CELLS_VOLTAGE: 7 Vector__XXX
 SG_ voltage_2 : 40|16@1+ (7.629510948348211e-05,0) [0|5] "" Vector__XXX
 SG_ voltage_1 : 24|16@1+ (7.629510948348211e-05,0) [0|5] "" Vector__XXX
 SG_ voltage_0 : 8|16@1+ (7.629510948348211e-05,0) [0|5] "" Vector__XXX
 SG_ start_index : 0|8@1+ (1,0) [0|255] "" Vector__XXX

BO_ 1656 LV_CELLS_VOLTAGE_STATS: 8 Vector__XXX
 SG_ avg : 48|16@1+ (7.629510948348211e-05,0) [0|5] "" Vector__XXX
 SG_ delta : 32|16@1+ (7.629510948348211e-05,0) [0|5] "" Vector__XXX
 SG_ min : 16|16@1+ (7.629510948348211e-05,0) [0|5] "" Vector__XXX
 SG_ max : 0|16@1+ (7.629510948348211e-05,0) [0|5] "" Vector__XXX

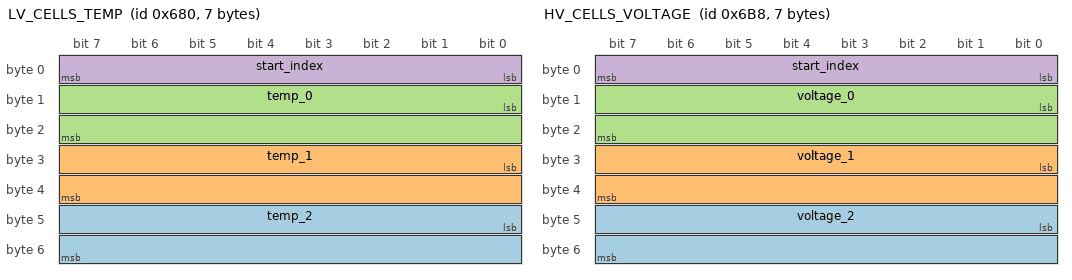
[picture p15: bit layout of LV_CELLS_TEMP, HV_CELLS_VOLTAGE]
BO_ 1664 LV_CELLS_TEMP: 7 Vector__XXX
 SG_ temp_2 : 40|16@1+ (0.0061038881767686015,-20) [-20|80] "" Vector__XXX
 SG_ temp_1 : 24|16@1+ (0.0061038881767686015,-20) [-20|80] "" Vector__XXX
 SG_ temp_0 : 8|16@1+ (0.0061038881767686015,-20) [-20|80] "" Vector__XXX
 SG_ start_index : 0|8@1+ (1,0) [0|255] "" Vector__XXX

BO_ 1672 LV_CELLS_TEMP_STATS: 6 Vector__XXX
 SG_ avg : 32|16@1+ (0.0061038881767686015,-20) [-20|80] "" Vector__XXX
 SG_ min : 16|16@1+ (0.0061038881767686015,-20) [-20|80] "" Vector__XXX
 SG_ max : 0|16@1+ (0.0061038881767686015,-20) [-20|80] "" Vector__XXX

BO_ 1680 HV_CURRENT: 2 Vector__XXX
 SG_ current : 0|16@1+ (0.006103608758678569,-200) [-200|200] "" Vector__XXX

BO_ 1688 HV_POWER: 2 Vector__XXX
 SG_ power : 0|16@1+ (0.0030518043793392844,-100) [-100|100] "" Vector__XXX

BO_ 1696 HV_ENERGY: 2 Vector__XXX
 SG_ energy : 0|16@1+ (0.10681315327687495,0) [0|7000] "" Vector__XXX

BO_ 1704 HV_SOC: 1 Vector__XXX
 SG_ soc : 0|8@1+ (0.39215686274509803,0) [0|100] "" Vector__XXX

BO_ 1712 HV_TOTAL_VOLTAGE: 6 Vector__XXX
 SG_ bus : 32|16@1+ (0.9001956947162426,0) [0|460] "" Vector__XXX
 SG_ sum_cell : 16|16@1+ (0.9001956947162426,0) [0|460] "" Vector__XXX
 SG_ pack : 0|16@1+ (0.9001956947162426,0) [0|460] "" Vector__XXX

BO_ 1720 HV_CELLS_VOLTAGE: 7 Vector__XXX
 SG_ voltage_2 : 40|16@1+ (7.629510948348211e-05,0) [0|5] "" Vector__XXX
 SG_ voltage_1 : 24|16@1+ (7.629510948348211e-05,0) [0|5] "" Vector__XXX
 SG_ voltage_0 : 8|16@1+ (7.629510948348211e-05,0) [0|5] "" Vector__XXX
 SG_ start_index : 0|8@1+ (1,0) [0|255] "" Vector__XXX

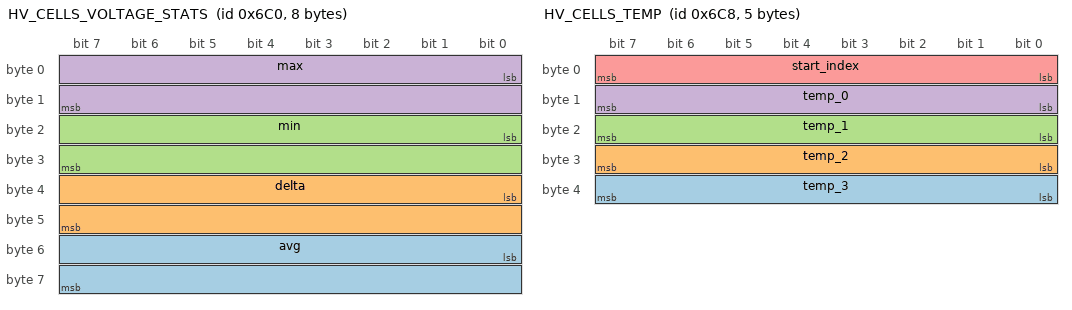
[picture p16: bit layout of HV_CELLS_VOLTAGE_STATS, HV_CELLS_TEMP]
BO_ 1728 HV_CELLS_VOLTAGE_STATS: 8 Vector__XXX
 SG_ avg : 48|16@1+ (7.629510948348211e-05,0) [0|5] "" Vector__XXX
 SG_ delta : 32|16@1+ (0.007019150072480354,0) [0|460] "" Vector__XXX
 SG_ min : 16|16@1+ (7.629510948348211e-05,0) [0|5] "" Vector__XXX
 SG_ max : 0|16@1+ (7.629510948348211e-05,0) [0|5] "" Vector__XXX

BO_ 1736 HV_CELLS_TEMP: 5 Vector__XXX
 SG_ temp_3 : 32|8@1+ (0.39215686274509803,-20) [-20|80] "" Vector__XXX
 SG_ temp_2 : 24|8@1+ (0.39215686274509803,-20) [-20|80] "" Vector__XXX
 SG_ temp_1 : 16|8@1+ (0.39215686274509803,-20) [-20|80] "" Vector__XXX
 SG_ temp_0 : 8|8@1+ (0.39215686274509803,-20) [-20|80] "" Vector__XXX
 SG_ start_index : 0|8@1+ (1,0) [0|255] "" Vector__XXX

BO_ 1744 HV_CELLS_TEMP_STATS: 6 Vector__XXX
 SG_ avg : 32|16@1+ (0.0061038881767686015,-20) [-20|80] "" Vector__XXX
 SG_ min : 16|16@1+ (0.0061038881767686015,-20) [-20|80] "" Vector__XXX
 SG_ max : 0|16@1+ (0.0061038881767686015,-20) [-20|80] "" Vector__XXX

BO_ 1752 ECU_STEER_ACTUATOR_STATUS: 1 Vector__XXX
 SG_ status : 0|1@1+ (1,0) [0|1] "" Vector__XXX

BO_ 1104 ECU_SET_STEER_ACTUATOR_STATUS_STEERING_WHEEL: 1 Vector__XXX
 SG_ status : 0|1@1+ (1,0) [0|1] "" Vector__XXX

BO_ 1112 ECU_SET_STEER_ACTUATOR_STATUS_TLM: 1 Vector__XXX
 SG_ status : 0|1@1+ (1,0) [0|1] "" Vector__XXX

BO_ 1760 ECU_SET_STEER_ACTUATOR_ANGLE: 2 Vector__XXX
 SG_ angle : 0|16@1+ (0.005493247882810712,-180) [-180|180] "" Vector__XXX

BO_ 1768 ECU_STEER_ACTUATOR_CURRENT: 1 Vector__XXX
 SG_ current : 0|8@1+ (0.19607843137254902,-25) [-25|25] "" Vector__XXX

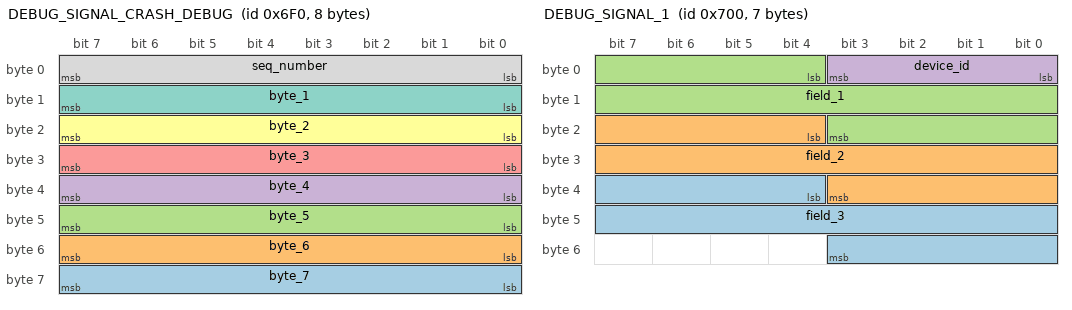
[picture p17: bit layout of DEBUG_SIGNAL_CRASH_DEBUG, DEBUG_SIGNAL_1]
BO_ 1776 DEBUG_SIGNAL_CRASH_DEBUG: 8 Vector__XXX
 SG_ byte_7 : 56|8@1+ (1,0) [0|255] "" Vector__XXX
 SG_ byte_6 : 48|8@1+ (1,0) [0|255] "" Vector__XXX
 SG_ byte_5 : 40|8@1+ (1,0) [0|255] "" Vector__XXX
 SG_ byte_4 : 32|8@1+ (1,0) [0|255] "" Vector__XXX
 SG_ byte_3 : 24|8@1+ (1,0) [0|255] "" Vector__XXX
 SG_ byte_2 : 16|8@1+ (1,0) [0|255] "" Vector__XXX
 SG_ byte_1 : 8|8@1+ (1,0) [0|255] "" Vector__XXX
 SG_ seq_number : 0|8@1+ (1,0) [0|255] "" Vector__XXX

BO_ 1784 DEBUG_SIGNAL_CRASH_DEBUG_ACK: 1 Vector__XXX
 SG_ seq_number : 0|8@1+ (1,0) [0|255] "" Vector__XXX

BO_ 1792 DEBUG_SIGNAL_1: 7 Vector__XXX
 SG_ field_3 : 36|16@1+ (3.0518043793392844e-05,-1) [-1|1] "" Vector__XXX
 SG_ field_2 : 20|16@1+ (3.0518043793392844e-05,-1) [-1|1] "" Vector__XXX
 SG_ field_1 : 4|16@1+ (3.0518043793392844e-05,-1) [-1|1] "" Vector__XXX
 SG_ device_id : 0|4@1+ (1,0) [0|15] "" Vector__XXX

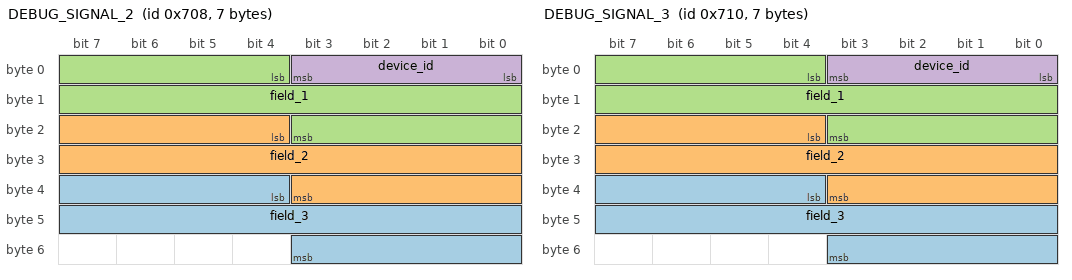
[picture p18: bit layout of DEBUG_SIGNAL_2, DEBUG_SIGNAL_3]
BO_ 1800 DEBUG_SIGNAL_2: 7 Vector__XXX
 SG_ field_3 : 36|16@1+ (3.0518043793392844e-05,-1) [-1|1] "" Vector__XXX
 SG_ field_2 : 20|16@1+ (3.0518043793392844e-05,-1) [-1|1] "" Vector__XXX
 SG_ field_1 : 4|16@1+ (3.0518043793392844e-05,-1) [-1|1] "" Vector__XXX
 SG_ device_id : 0|4@1+ (1,0) [0|15] "" Vector__XXX

BO_ 1808 DEBUG_SIGNAL_3: 7 Vector__XXX
 SG_ field_3 : 36|16@1+ (3.0518043793392844e-05,-1) [-1|1] "" Vector__XXX
 SG_ field_2 : 20|16@1+ (3.0518043793392844e-05,-1) [-1|1] "" Vector__XXX
 SG_ field_1 : 4|16@1+ (3.0518043793392844e-05,-1) [-1|1] "" Vector__XXX
 SG_ device_id : 0|4@1+ (1,0) [0|15] "" Vector__XXX

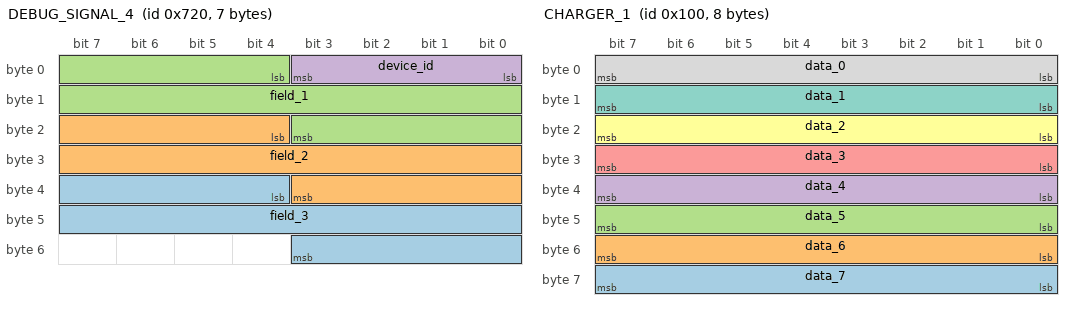
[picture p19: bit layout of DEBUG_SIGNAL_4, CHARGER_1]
BO_ 1824 DEBUG_SIGNAL_4: 7 Vector__XXX
 SG_ field_3 : 36|16@1+ (3.0518043793392844e-05,-1) [-1|1] "" Vector__XXX
 SG_ field_2 : 20|16@1+ (3.0518043793392844e-05,-1) [-1|1] "" Vector__XXX
 SG_ field_1 : 4|16@1+ (3.0518043793392844e-05,-1) [-1|1] "" Vector__XXX
 SG_ device_id : 0|4@1+ (1,0) [0|15] "" Vector__XXX

BO_ 256 CHARGER_1: 8 Vector__XXX
 SG_ data_7 : 56|8@1+ (1,0) [0|255] "" Vector__XXX
 SG_ data_6 : 48|8@1+ (1,0) [0|255] "" Vector__XXX
 SG_ data_5 : 40|8@1+ (1,0) [0|255] "" Vector__XXX
 SG_ data_4 : 32|8@1+ (1,0) [0|255] "" Vector__XXX
 SG_ data_3 : 24|8@1+ (1,0) [0|255] "" Vector__XXX
 SG_ data_2 : 16|8@1+ (1,0) [0|255] "" Vector__XXX
 SG_ data_1 : 8|8@1+ (1,0) [0|255] "" Vector__XXX
 SG_ data_0 : 0|8@1+ (1,0) [0|255] "" Vector__XXX

BO_ 272 CHARGER_2: 8 Vector__XXX
 SG_ data_7 : 56|8@1+ (1,0) [0|255] "" Vector__XXX
 SG_ data_6 : 48|8@1+ (1,0) [0|255] "" Vector__XXX
 SG_ data_5 : 40|8@1+ (1,0) [0|255] "" Vector__XXX
 SG_ data_4 : 32|8@1+ (1,0) [0|255] "" Vector__XXX
 SG_ data_3 : 24|8@1+ (1,0) [0|255] "" Vector__XXX
 SG_ data_2 : 16|8@1+ (1,0) [0|255] "" Vector__XXX
 SG_ data_1 : 8|8@1+ (1,0) [0|255] "" Vector__XXX
 SG_ data_0 : 0|8@1+ (1,0) [0|255] "" Vector__XXX

BO_ 288 CHARGER_3: 8 Vector__XXX
 SG_ data_7 : 56|8@1+ (1,0) [0|255] "" Vector__XXX
 SG_ data_6 : 48|8@1+ (1,0) [0|255] "" Vector__XXX
 SG_ data_5 : 40|8@1+ (1,0) [0|255] "" Vector__XXX
 SG_ data_4 : 32|8@1+ (1,0) [0|255] "" Vector__XXX
 SG_ data_3 : 24|8@1+ (1,0) [0|255] "" Vector__XXX
 SG_ data_2 : 16|8@1+ (1,0) [0|255] "" Vector__XXX
 SG_ data_1 : 8|8@1+ (1,0) [0|255] "" Vector__XXX
 SG_ data_0 : 0|8@1+ (1,0) [0|255] "" Vector__XXX

BO_ 304 CHARGER_4: 8 Vector__XXX
 SG_ data_7 : 56|8@1+ (1,0) [0|255] "" Vector__XXX
 SG_ data_6 : 48|8@1+ (1,0) [0|255] "" Vector__XXX
 SG_ data_5 : 40|8@1+ (1,0) [0|255] "" Vector__XXX
 SG_ data_4 : 32|8@1+ (1,0) [0|255] "" Vector__XXX
 SG_ data_3 : 24|8@1+ (1,0) [0|255] "" Vector__XXX
 SG_ data_2 : 16|8@1+ (1,0) [0|255] "" Vector__XXX
 SG_ data_1 : 8|8@1+ (1,0) [0|255] "" Vector__XXX
 SG_ data_0 : 0|8@1+ (1,0) [0|255] "" Vector__XXX

BO_ 320 CHARGER_5: 8 Vector__XXX
 SG_ data_7 : 56|8@1+ (1,0) [0|255] "" Vector__XXX
 SG_ data_6 : 48|8@1+ (1,0) [0|255] "" Vector__XXX
 SG_ data_5 : 40|8@1+ (1,0) [0|255] "" Vector__XXX
 SG_ data_4 : 32|8@1+ (1,0) [0|255] "" Vector__XXX
 SG_ data_3 : 24|8@1+ (1,0) [0|255] "" Vector__XXX
 SG_ data_2 : 16|8@1+ (1,0) [0|255] "" Vector__XXX
 SG_ data_1 : 8|8@1+ (1,0) [0|255] "" Vector__XXX
 SG_ data_0 : 0|8@1+ (1,0) [0|255] "" Vector__XXX

BO_ 336 CHARGER_6: 8 Vector__XXX
 SG_ data_7 : 56|8@1+ (1,0) [0|255] "" Vector__XXX
 SG_ data_6 : 48|8@1+ (1,0) [0|255] "" Vector__XXX
 SG_ data_5 : 40|8@1+ (1,0) [0|255] "" Vector__XXX
 SG_ data_4 : 32|8@1+ (1,0) [0|255] "" Vector__XXX
 SG_ data_3 : 24|8@1+ (1,0) [0|255] "" Vector__XXX
 SG_ data_2 : 16|8@1+ (1,0) [0|255] "" Vector__XXX
 SG_ data_1 : 8|8@1+ (1,0) [0|255] "" Vector__XXX
 SG_ data_0 : 0|8@1+ (1,0) [0|255] "" Vector__XXX

BO_ 344 CHARGER_7: 8 Vector__XXX
 SG_ data_7 : 56|8@1+ (1,0) [0|255] "" Vector__XXX
 SG_ data_6 : 48|8@1+ (1,0) [0|255] "" Vector__XXX
 SG_ data_5 : 40|8@1+ (1,0) [0|255] "" Vector__XXX
 SG_ data_4 : 32|8@1+ (1,0) [0|255] "" Vector__XXX
 SG_ data_3 : 24|8@1+ (1,0) [0|255] "" Vector__XXX
 SG_ data_2 : 16|8@1+ (1,0) [0|255] "" Vector__XXX
 SG_ data_1 : 8|8@1+ (1,0) [0|255] "" Vector__XXX
 SG_ data_0 : 0|8@1+ (1,0) [0|255] "" Vector__XXX

BO_ 352 CHARGER_8: 8 Vector__XXX
 SG_ data_7 : 56|8@1+ (1,0) [0|255] "" Vector__XXX
 SG_ data_6 : 48|8@1+ (1,0) [0|255] "" Vector__XXX
 SG_ data_5 : 40|8@1+ (1,0) [0|255] "" Vector__XXX
 SG_ data_4 : 32|8@1+ (1,0) [0|255] "" Vector__XXX
 SG_ data_3 : 24|8@1+ (1,0) [0|255] "" Vector__XXX
 SG_ data_2 : 16|8@1+ (1,0) [0|255] "" Vector__XXX
 SG_ data_1 : 8|8@1+ (1,0) [0|255] "" Vector__XXX
 SG_ data_0 : 0|8@1+ (1,0) [0|255] "" Vector__XXX

BO_ 368 CHARGER_9: 8 Vector__XXX
 SG_ data_7 : 56|8@1+ (1,0) [0|255] "" Vector__XXX
 SG_ data_6 : 48|8@1+ (1,0) [0|255] "" Vector__XXX
 SG_ data_5 : 40|8@1+ (1,0) [0|255] "" Vector__XXX
 SG_ data_4 : 32|8@1+ (1,0) [0|255] "" Vector__XXX
 SG_ data_3 : 24|8@1+ (1,0) [0|255] "" Vector__XXX
 SG_ data_2 : 16|8@1+ (1,0) [0|255] "" Vector__XXX
 SG_ data_1 : 8|8@1+ (1,0) [0|255] "" Vector__XXX
 SG_ data_0 : 0|8@1+ (1,0) [0|255] "" Vector__XXX

BO_ 384 CHARGER_10: 8 Vector__XXX
 SG_ data_7 : 56|8@1+ (1,0) [0|255] "" Vector__XXX
 SG_ data_6 : 48|8@1+ (1,0) [0|255] "" Vector__XXX
 SG_ data_5 : 40|8@1+ (1,0) [0|255] "" Vector__XXX
 SG_ data_4 : 32|8@1+ (1,0) [0|255] "" Vector__XXX
 SG_ data_3 : 24|8@1+ (1,0) [0|255] "" Vector__XXX
 SG_ data_2 : 16|8@1+ (1,0) [0|255] "" Vector__XXX
 SG_ data_1 : 8|8@1+ (1,0) [0|255] "" Vector__XXX
 SG_ data_0 : 0|8@1+ (1,0) [0|255] "" Vector__XXX

BO_ 392 CHARGER_11: 8 Vector__XXX
 SG_ data_7 : 56|8@1+ (1,0) [0|255] "" Vector__XXX
 SG_ data_6 : 48|8@1+ (1,0) [0|255] "" Vector__XXX
 SG_ data_5 : 40|8@1+ (1,0) [0|255] "" Vector__XXX
 SG_ data_4 : 32|8@1+ (1,0) [0|255] "" Vector__XXX
 SG_ data_3 : 24|8@1+ (1,0) [0|255] "" Vector__XXX
 SG_ data_2 : 16|8@1+ (1,0) [0|255] "" Vector__XXX
 SG_ data_1 : 8|8@1+ (1,0) [0|255] "" Vector__XXX
 SG_ data_0 : 0|8@1+ (1,0) [0|255] "" Vector__XXX

BO_ 400 CHARGER_12: 8 Vector__XXX
 SG_ data_7 : 56|8@1+ (1,0) [0|255] "" Vector__XXX
 SG_ data_6 : 48|8@1+ (1,0) [0|255] "" Vector__XXX
 SG_ data_5 : 40|8@1+ (1,0) [0|255] "" Vector__XXX
 SG_ data_4 : 32|8@1+ (1,0) [0|255] "" Vector__XXX
 SG_ data_3 : 24|8@1+ (1,0) [0|255] "" Vector__XXX
 SG_ data_2 : 16|8@1+ (1,0) [0|255] "" Vector__XXX
 SG_ data_1 : 8|8@1+ (1,0) [0|255] "" Vector__XXX
 SG_ data_0 : 0|8@1+ (1,0) [0|255] "" Vector__XXX

BO_ 408 CHARGER_13: 8 Vector__XXX
 SG_ data_7 : 56|8@1+ (1,0) [0|255] "" Vector__XXX
 SG_ data_6 : 48|8@1+ (1,0) [0|255] "" Vector__XXX
 SG_ data_5 : 40|8@1+ (1,0) [0|255] "" Vector__XXX
 SG_ data_4 : 32|8@1+ (1,0) [0|255] "" Vector__XXX
 SG_ data_3 : 24|8@1+ (1,0) [0|255] "" Vector__XXX
 SG_ data_2 : 16|8@1+ (1,0) [0|255] "" Vector__XXX
 SG_ data_1 : 8|8@1+ (1,0) [0|255] "" Vector__XXX
 SG_ data_0 : 0|8@1+ (1,0) [0|255] "" Vector__XXX

BO_ 416 CHARGER_14: 8 Vector__XXX
 SG_ data_7 : 56|8@1+ (1,0) [0|255] "" Vector__XXX
 SG_ data_6 : 48|8@1+ (1,0) [0|255] "" Vector__XXX
 SG_ data_5 : 40|8@1+ (1,0) [0|255] "" Vector__XXX
 SG_ data_4 : 32|8@1+ (1,0) [0|255] "" Vector__XXX
 SG_ data_3 : 24|8@1+ (1,0) [0|255] "" Vector__XXX
 SG_ data_2 : 16|8@1+ (1,0) [0|255] "" Vector__XXX
 SG_ data_1 : 8|8@1+ (1,0) [0|255] "" Vector__XXX
 SG_ data_0 : 0|8@1+ (1,0) [0|255] "" Vector__XXX

BO_ 432 CHARGER_15: 8 Vector__XXX
 SG_ data_7 : 56|8@1+ (1,0) [0|255] "" Vector__XXX
 SG_ data_6 : 48|8@1+ (1,0) [0|255] "" Vector__XXX
 SG_ data_5 : 40|8@1+ (1,0) [0|255] "" Vector__XXX
 SG_ data_4 : 32|8@1+ (1,0) [0|255] "" Vector__XXX
 SG_ data_3 : 24|8@1+ (1,0) [0|255] "" Vector__XXX
 SG_ data_2 : 16|8@1+ (1,0) [0|255] "" Vector__XXX
 SG_ data_1 : 8|8@1+ (1,0) [0|255] "" Vector__XXX
 SG_ data_0 : 0|8@1+ (1,0) [0|255] "" Vector__XXX

BO_ 448 CHARGER_16: 8 Vector__XXX
 SG_ data_7 : 56|8@1+ (1,0) [0|255] "" Vector__XXX
 SG_ data_6 : 48|8@1+ (1,0) [0|255] "" Vector__XXX
 SG_ data_5 : 40|8@1+ (1,0) [0|255] "" Vector__XXX
 SG_ data_4 : 32|8@1+ (1,0) [0|255] "" Vector__XXX
 SG_ data_3 : 24|8@1+ (1,0) [0|255] "" Vector__XXX
 SG_ data_2 : 16|8@1+ (1,0) [0|255] "" Vector__XXX
 SG_ data_1 : 8|8@1+ (1,0) [0|255] "" Vector__XXX
 SG_ data_0 : 0|8@1+ (1,0) [0|255] "" Vector__XXX

BO_ 464 CHARGER_17: 8 Vector__XXX
 SG_ data_7 : 56|8@1+ (1,0) [0|255] "" Vector__XXX
 SG_ data_6 : 48|8@1+ (1,0) [0|255] "" Vector__XXX
 SG_ data_5 : 40|8@1+ (1,0) [0|255] "" Vector__XXX
 SG_ data_4 : 32|8@1+ (1,0) [0|255] "" Vector__XXX
 SG_ data_3 : 24|8@1+ (1,0) [0|255] "" Vector__XXX
 SG_ data_2 : 16|8@1+ (1,0) [0|255] "" Vector__XXX
 SG_ data_1 : 8|8@1+ (1,0) [0|255] "" Vector__XXX
 SG_ data_0 : 0|8@1+ (1,0) [0|255] "" Vector__XXX

BO_ 480 CHARGER_18: 8 Vector__XXX
 SG_ data_7 : 56|8@1+ (1,0) [0|255] "" Vector__XXX
 SG_ data_6 : 48|8@1+ (1,0) [0|255] "" Vector__XXX
 SG_ data_5 : 40|8@1+ (1,0) [0|255] "" Vector__XXX
 SG_ data_4 : 32|8@1+ (1,0) [0|255] "" Vector__XXX
 SG_ data_3 : 24|8@1+ (1,0) [0|255] "" Vector__XXX
 SG_ data_2 : 16|8@1+ (1,0) [0|255] "" Vector__XXX
 SG_ data_1 : 8|8@1+ (1,0) [0|255] "" Vector__XXX
 SG_ data_0 : 0|8@1+ (1,0) [0|255] "" Vector__XXX

BO_ 496 CHARGER_19: 8 Vector__XXX
 SG_ data_7 : 56|8@1+ (1,0) [0|255] "" Vector__XXX
 SG_ data_6 : 48|8@1+ (1,0) [0|255] "" Vector__XXX
 SG_ data_5 : 40|8@1+ (1,0) [0|255] "" Vector__XXX
 SG_ data_4 : 32|8@1+ (1,0) [0|255] "" Vector__XXX
 SG_ data_3 : 24|8@1+ (1,0) [0|255] "" Vector__XXX
 SG_ data_2 : 16|8@1+ (1,0) [0|255] "" Vector__XXX
 SG_ data_1 : 8|8@1+ (1,0) [0|255] "" Vector__XXX
 SG_ data_0 : 0|8@1+ (1,0) [0|255] "" Vector__XXX

CM_ SG_ 1818 LAD_D_ParamRp "Diag responded data to host";
CM_ SG_ 1816 LAD_D_ParamRq "Diag requested data from host";
CM_ SG_ 1556 NLG5_W_SC_M "Save-Charging-Mode reduces primary current to 3.95 A as long as one of the four internal temperature sensors indicates -18° C or less.
";
CM_ SG_ 1556 NLG5_W_OD "LED Output driver defective, LEDs can´t be controlled by NLG5 anymore. Charging is still possible.
";
CM_ SG_ 1556 NLG5_W_CM_NA "NLG5 Control message not active";
CM_ SG_ 1556 NLG5_W_C_VOR "Commanded value is out of specified range; max or min applicable value is assumed instead";
CM_ SG_ 1556 NLG5_W_PL_IT "Output power limited by charger internal overtemperature";
CM_ SG_ 1556 NLG5_W_PL_BV "Output power limited by low battery voltage";
CM_ SG_ 1556 NLG5_W_PL_MV "Output power limited by low mains voltage";
CM_ SG_ 1556 NLG5_E_SDT_CT "Emergency Shutdown Threshold 'Charging Time' is exceeded; see ChargeStar help section 'protective features';  error can only be cleared by cycling power ON-OFF-ON";
CM_ SG_ 1556 NLG5_E_SDT_AH "Emergency Shutdown Threshold 'Amp Hours' is exceeded; see ChargeStar help section 'protective features';  error can only be cleared by cycling power ON-OFF-ON";
CM_ SG_ 1556 NLG5_E_SDT_BV "Emergency Shutdown Threshold 'Battery Voltage' is exceeded; see ChargeStar help section 'protective features';  error can only be cleared by cycling power ON-OFF-ON";
CM_ SG_ 1556 NLG5_E_SDT_BT "Emergency Shutdown Threshold 'Battery Temperature' is exceeded; see ChargeStar help section 'protective features';  error can only be cleared by cycling power ON-OFF-ON";
CM_ SG_ 1556 NLG5_E_C_RX "CAN receiver buffer >127";
CM_ SG_ 1556 NLG5_E_C_TX "CAN transmit buffer >127";
CM_ SG_ 1556 NLG5_E_C_OFF "CAN off, transmit buffer >255";
CM_ SG_ 1556 NLG5_E_C_TO "CAN timeout, no control message received for >300ms";
CM_ SG_ 1556 NLG5_E_INIT "Initialization error";
CM_ SG_ 1556 NLG5_E_WDT "Internal Watchdog Timeout";
CM_ SG_ 1556 NLG5_E_EP_CRC "Pow EEPROM checksum failure";
CM_ SG_ 1556 NLG5_E_ES_CRC "Sys EEPROM checksum failure";
CM_ SG_ 1556 NLG5_E_NV_CRC "NVSRAM check sum failure; contains most of the scaling & calibration values, CAN ID's and  charging profile etc.";
CM_ SG_ 1556 NLG5_E_F_CRC "Flash memory checksum failure";
CM_ SG_ 1556 NLG5_E_T_EXT3 "Ext. temperature sensor 3 defective (if enabled)";
CM_ SG_ 1556 NLG5_E_T_EXT2 "Ext. temperature sensor 2 defective (if enabled)";
CM_ SG_ 1556 NLG5_E_T_EXT1 "Ext. temperature sensor 1 defective (if enabled)";
CM_ SG_ 1556 NLG5_E_T_TR "Temperature sensor for transformer defective";
CM_ SG_ 1556 NLG5_E_T_DIO "Temperature sensor for diodes defective";
CM_ SG_ 1556 NLG5_E_T_POW "Temperature sensor for prim power stage defective";
CM_ SG_ 1556 NLG5_E_T_C "Temperature sensor for prim capacitor defective";
CM_ SG_ 1556 NLG5_E_B_P "wrong battery polarity;  error can only be cleared by cycling power ON-OFF-ON";
CM_ SG_ 1556 NLG5_E_MF "Mains fuse defective";
CM_ SG_ 1556 NLG5_E_OF "output fuse defective";
CM_ SG_ 1556 NLG5_E_P_MV "plausibility mains voltage measurement wrong";
CM_ SG_ 1556 NLG5_E_P_OM "plausibility battery output voltage measurement wrong";
CM_ SG_ 1556 NLG5_E_SC "power stage short circuit condition detected; error can only be cleared by cycling power ON-OFF-ON";
CM_ SG_ 1556 NLG5_E_MOV_I "Mains overvoltage 1 detected";
CM_ SG_ 1556 NLG5_E_MOV_II "Mains overvoltage 2 detected";
CM_ SG_ 1556 NLG5_E_OOV "battery output overvoltage; error can only be cleared by cycling power ON-OFF-ON 
";
CM_ SG_ 1555 NLG5_TMP_EXT3 "Value of external battery temperature sensor #3 (if connected and enabled)";
CM_ SG_ 1555 NLG5_TEMP_EXT2 "Value of external battery temperature sensor #2 (if connected and enabled)";
CM_ SG_ 1555 NLG5_TMP_EXT1 "Value of external battery temperature sensor #1 (if connected and enabled)";
CM_ SG_ 1555 NLG5_P_TMP "Power stage temperature";
CM_ SG_ 1554 NLG5_OC_BO "output current of the booster (if one is present and active)";
CM_ SG_ 1554 NLG5_AHC_EXT "Charge balance obtained via  Ext. Ah counter connected to DI1 / DI2";
CM_ SG_ 1554 NLG5_ABV "Aux battery voltage";
CM_ SG_ 1554 NLG5_S_MC_M_PI "Value of mains current limit, commanded by the 'power indicator' (PI) analog input signal";
CM_ SG_ 1554 NLG5_S_MC_M_CP "Value of mains current limit, commanded by the control pilot (SAE J1772) signal";
CM_ SG_ 1553 NLG5_OC_ACT "output current to the battery";
CM_ SG_ 1553 NLG5_OV_ACT "Actual battery output voltage";
CM_ SG_ 1553 NLG5_MV_ACT "Actual mains voltage";
CM_ SG_ 1553 NLG5_MC_ACT "Actual mains current";
CM_ SG_ 1552 NLG5_S_AAC "AUX 12 V Automatic Charging Active";
CM_ SG_ 1552 NLG5_S_L_T_BATT "Output power limited by battery temperature";
CM_ SG_ 1552 NLG5_S_L_T_TR "Output power limited by temperature of transformer";
CM_ SG_ 1552 NLG5_S_L_T_DIO "Output power limited by temperature of diodes";
CM_ SG_ 1552 NLG5_S_L_T_POW "Output power limited by temperature of power stage";
CM_ SG_ 1552 NLG5_S_L_T_CPRIM "Output power limited by temperature of primary capacitors";
CM_ SG_ 1552 NLG5_S_L_MO_MAX "Output power limited by maximum output voltage capability of NLG5";
CM_ SG_ 1552 NLG5_S_L_OC_MAX "Output power limited by maximum output current capability of NLG5";
CM_ SG_ 1552 NLG5_S_L_MC_MAX "Output power limited by maximum mains current capability of NLG5";
CM_ SG_ 1552 NLG5_S_L_PMAX "Output power limited by maximum power capability of NLG5";
CM_ SG_ 1552 NLG5_S_L_CP "Output power limited by control pilot signal (SAE J1772)";
CM_ SG_ 1552 NLG5_S_L_PI "Output power limited by analog input 'power indicator' (PI) limit";
CM_ SG_ 1552 NLG5_S_L_MC "Output power limited by mains current limit";
CM_ SG_ 1552 NLG5_S_L_OC "Output power limited by battery output current limit";
CM_ SG_ 1552 NLG5_S_L_OV "Output power limited by battery output voltage limit";
CM_ SG_ 1552 NLG5_S_BPD_II "Bypass detection bit 2; 00: no bypass, 01: DC bypass detected, 10:AC bypass in phase, 11: AC bypass not in phase";
CM_ SG_ 1552 NLG5_S_BPD_I "Bypass detection bit 1; 00: no bypass, 01: DC bypass detected, 10:AC bypass in phase, 11: AC bypass not in phase";
CM_ SG_ 1552 NLG5_S_CP_DT "Control pilot signal (SAE J1772) detected ";
CM_ SG_ 1552 NLG5_S_UM_II "US mains level 2 (240VAC / 60Hz) detected";
CM_ SG_ 1552 NLG5_S_UM_I "US mains level 1 (120VAC / 60Hz) detected";
CM_ SG_ 1552 NLG5_S_EUM "European mains input detected (230V, 50Hz)";
CM_ SG_ 1552 NLG5_S_FAN "Charger cooling fan is active";
CM_ SG_ 1552 NLG5_S_WAR "Warning condition on, i.e. charging power limited due to any limiting condition; red LED is blinking";
CM_ SG_ 1552 NLG5_S_ERR "An error has been detected, red LED is ON, no power is output";
CM_ SG_ 1552 NLG5_S_HE "Indicates if hardware enabled, i.e. a hi or lo signal is fed to the 'Power On' pin (pin3 of control connector)";
CM_ SG_ 1560 NLG5_OC_COM "Desired battery current. Must always contain a valid value in order to keep on charging.";
CM_ SG_ 1560 NLG5_OV_COM "Desired voltage to be output to the battery. Must always contain a valid value in order to keep on charging.";
CM_ SG_ 1560 NLG5_MC_MAX "Maximum current to be drawn from the mains outlet, usually 16A. Must always contain a valid value in order to keep on charging.";
CM_ SG_ 1560 NLG5_C_MR "Enables CP-State C to request mains voltage";
CM_ SG_ 1560 NLG5_C_CP_V "special signal to tell a charging station equipped with the Control Pilot interface (SAE J1772) to switch on the facility's ventilation (in order to get rid of battery gases like hydrogen, e.g.)";
CM_ SG_ 1560 NLG5_C_C_EL "cycle this value 0-1-0 to clear all latched charger errors ";
CM_ SG_ 1560 NLG5_C_C_EN "Must be ON to enable power stage of the charger";
CM_ BO_ 700 "Steering wheel version: build-time timestamp and canlib build-time timestamp";
CM_ BO_ 701 "Ecu version: build-time timestamp and canlib build-time timestamp";
CM_ BO_ 703 "Telemetry version: build-time timestamp and canlib build-time timestamp";
CM_ BO_ 704 "Telemetry version: build-time timestamp and canlib build-time timestamp";
CM_ BO_ 702 "Hv mainboard version: build-time timestamp and canlib build-time timestamp";
CM_ BO_ 705 "Hv cellboard version: build-time timestamp and canlib build-time timestamp";
CM_ BO_ 560 "Bms hv status";
CM_ BO_ 680 "Torques and signals calculated by the controls algorithms";
CM_ BO_ 688 "Power maps used by the control algorithm. (ECU checks if are coherent with the ones in the ECU)";
BA_DEF_  "Bus Speed" STRING ;
BA_DEF_ SG_  "GenSigSendType" ENUM  "Cyclic","OnWrite","OnWriteWithRepetition","OnChange","OnChangeWithRepetition","IfActive","IfActiveWithRepetition","NoSigSendType";
BA_DEF_ BO_  "GenMsgCycleTime" INT 0 0;
BA_DEF_ BO_  "GenMsgSendType" ENUM  "Cyclic","not_used","not_used","not_used","not_used","Cyclic","not_used","IfActive","NoMsgSendType";
BA_DEF_  "DBName" STRING ;
BA_DEF_  "BusType" STRING ;
BA_DEF_DEF_  "Bus Speed" "500k";
BA_DEF_DEF_  "GenSigSendType" "Cyclic";
BA_DEF_DEF_  "GenMsgCycleTime" 0;
BA_DEF_DEF_  "GenMsgSendType" "NoMsgSendType";
BA_DEF_DEF_  "DBName" "";
BA_DEF_DEF_  "BusType" "CAN";
BA_ "DBName" "CANTemplate";
BA_ "GenMsgCycleTime" BO_ 700 1000;
BA_ "GenMsgCycleTime" BO_ 701 1000;
BA_ "GenMsgCycleTime" BO_ 703 1000;
BA_ "GenMsgCycleTime" BO_ 704 1000;
BA_ "GenMsgCycleTime" BO_ 702 1000;
BA_ "GenMsgCycleTime" BO_ 705 1000;
BA_ "GenMsgCycleTime" BO_ 32 20;
BA_ "GenMsgCycleTime" BO_ 512 500;
BA_ "GenMsgCycleTime" BO_ 1536 200;
BA_ "GenMsgCycleTime" BO_ 1024 200;
BA_ "GenMsgCycleTime" BO_ 520 50;
BA_ "GenMsgCycleTime" BO_ 528 50;
BA_ "GenMsgCycleTime" BO_ 536 50;
BA_ "GenMsgCycleTime" BO_ 544 50;
BA_ "GenMsgCycleTime" BO_ 552 20;
BA_ "GenMsgCycleTime" BO_ 560 20;
BA_ "GenMsgCycleTime" BO_ 40 50;
BA_ "GenMsgCycleTime" BO_ 48 50;
BA_ "GenMsgCycleTime" BO_ 1544 50;
BA_ "GenMsgCycleTime" BO_ 1032 200;
BA_ "GenMsgCycleTime" BO_ 1040 200;
BA_ "GenMsgCycleTime" BO_ 568 20;
BA_ "GenMsgCycleTime" BO_ 1568 200;
BA_ "GenMsgCycleTime" BO_ 1576 1000;
BA_ "GenMsgCycleTime" BO_ 1584 200;
BA_ "GenMsgCycleTime" BO_ 1592 200;
BA_ "GenMsgCycleTime" BO_ 1056 200;
BA_ "GenMsgCycleTime" BO_ 1064 200;
BA_ "GenMsgCycleTime" BO_ 576 20;
BA_ "GenMsgCycleTime" BO_ 584 50;
BA_ "GenMsgCycleTime" BO_ 592 50;
BA_ "GenMsgCycleTime" BO_ 600 50;
BA_ "GenMsgCycleTime" BO_ 608 50;
BA_ "GenMsgCycleTime" BO_ 616 50;
BA_ "GenMsgCycleTime" BO_ 624 20;
BA_ "GenMsgCycleTime" BO_ 80 50;
BA_ "GenMsgCycleTime" BO_ 1600 200;
BA_ "GenMsgCycleTime" BO_ 1072 200;
BA_ "GenMsgCycleTime" BO_ 632 20;
BA_ "GenMsgCycleTime" BO_ 1608 200;
BA_ "GenMsgCycleTime" BO_ 1080 200;
BA_ "GenMsgCycleTime" BO_ 640 20;
BA_ "GenMsgCycleTime" BO_ 88 50;
BA_ "GenMsgCycleTime" BO_ 1088 50;
BA_ "GenMsgCycleTime" BO_ 648 50;
BA_ "GenMsgCycleTime" BO_ 656 20;
BA_ "GenMsgCycleTime" BO_ 664 50;
BA_ "GenMsgCycleTime" BO_ 672 200;
BA_ "GenMsgCycleTime" BO_ 96 200;
BA_ "GenMsgCycleTime" BO_ 1616 200;
BA_ "GenMsgCycleTime" BO_ 1096 200;
BA_ "GenMsgCycleTime" BO_ 513 10;
BA_ "GenMsgCycleTime" BO_ 680 20;
BA_ "GenMsgCycleTime" BO_ 688 20;
BA_ "GenMsgCycleTime" BO_ 514 10;
BA_ "GenMsgCycleTime" BO_ 385 100;
BA_ "GenMsgCycleTime" BO_ 386 100;
BA_ "GenMsgCycleTime" BO_ 1624 50;
BA_ "GenMsgCycleTime" BO_ 1632 50;
BA_ "GenMsgCycleTime" BO_ 1640 50;
BA_ "GenMsgCycleTime" BO_ 1648 50;
BA_ "GenMsgCycleTime" BO_ 1656 50;
BA_ "GenMsgCycleTime" BO_ 1664 50;
BA_ "GenMsgCycleTime" BO_ 1672 50;
BA_ "GenMsgCycleTime" BO_ 1680 50;
BA_ "GenMsgCycleTime" BO_ 1688 50;
BA_ "GenMsgCycleTime" BO_ 1696 50;
BA_ "GenMsgCycleTime" BO_ 1704 50;
BA_ "GenMsgCycleTime" BO_ 1712 50;
BA_ "GenMsgCycleTime" BO_ 1720 50;
BA_ "GenMsgCycleTime" BO_ 1728 50;
BA_ "GenMsgCycleTime" BO_ 1736 50;
BA_ "GenMsgCycleTime" BO_ 1744 50;
BA_ "GenMsgCycleTime" BO_ 1752 200;
BA_ "GenMsgCycleTime" BO_ 1104 200;
BA_ "GenMsgCycleTime" BO_ 1112 200;
BA_ "GenMsgCycleTime" BO_ 1760 50;
BA_ "GenMsgCycleTime" BO_ 1768 200;
BA_ "GenMsgCycleTime" BO_ 1776 10;
BA_ "GenMsgCycleTime" BO_ 1784 10;
BA_ "GenMsgCycleTime" BO_ 1792 20;
BA_ "GenMsgCycleTime" BO_ 1800 20;
BA_ "GenMsgCycleTime" BO_ 1808 20;
BA_ "GenMsgCycleTime" BO_ 1824 20;
BA_ "GenMsgCycleTime" BO_ 256 100;
BA_ "GenMsgCycleTime" BO_ 272 100;
BA_ "GenMsgCycleTime" BO_ 288 1000;
BA_ "GenMsgCycleTime" BO_ 304 100;
BA_ "GenMsgCycleTime" BO_ 320 1000;
BA_ "GenMsgCycleTime" BO_ 336 1000;
BA_ "GenMsgCycleTime" BO_ 344 1000;
BA_ "GenMsgCycleTime" BO_ 352 1000;
BA_ "GenMsgCycleTime" BO_ 368 1000;
BA_ "GenMsgCycleTime" BO_ 384 1000;
BA_ "GenMsgCycleTime" BO_ 392 1000;
BA_ "GenMsgCycleTime" BO_ 400 1000;
BA_ "GenMsgCycleTime" BO_ 408 1000;
BA_ "GenMsgCycleTime" BO_ 416 1000;
BA_ "GenMsgCycleTime" BO_ 432 1000;
BA_ "GenMsgCycleTime" BO_ 448 1000;
BA_ "GenMsgCycleTime" BO_ 464 1000;
BA_ "GenMsgCycleTime" BO_ 480 1000;
BA_ "GenMsgCycleTime" BO_ 496 1000;
VAL_ 0 cellboard_id 0 "cellboard_0" 1 "cellboard_1" 2 "cellboard_2" 3 "cellboard_3" 4 "cellboard_4" 5 "cellboard_5" ;
VAL_ 0 forward 0 "off" 1 "on" ;
VAL_ 705 cellboard_id 0 "cellboard_0" 1 "cellboard_1" 2 "cellboard_2" 3 "cellboard_3" 4 "cellboard_4" 5 "cellboard_5" ;
VAL_ 1536 fans_override 0 "off" 1 "on" ;
VAL_ 1024 fans_override 0 "off" 1 "on" ;
VAL_ 520 feedback_sd_imd 0 "feedback_state_low" 1 "feedback_state_error" 2 "feedback_state_high" ;
VAL_ 520 feedback_sd_bms 0 "feedback_state_low" 1 "feedback_state_error" 2 "feedback_state_high" ;
VAL_ 520 feedback_sd_in 0 "feedback_state_low" 1 "feedback_state_error" 2 "feedback_state_high" ;
VAL_ 520 feedback_sd_out 0 "feedback_state_low" 1 "feedback_state_error" 2 "feedback_state_high" ;
VAL_ 520 feedback_sd_end 0 "feedback_state_low" 1 "feedback_state_error" 2 "feedback_state_high" ;
VAL_ 520 feedback_check_mux 0 "feedback_state_low" 1 "feedback_state_error" 2 "feedback_state_high" ;
VAL_ 520 feedback_imd_fault 0 "feedback_state_low" 1 "feedback_state_error" 2 "feedback_state_high" ;
VAL_ 520 feedback_tsp_over_60v_status 0 "feedback_state_low" 1 "feedback_state_error" 2 "feedback_state_high" ;
VAL_ 520 feedback_precharge_status 0 "feedback_state_low" 1 "feedback_state_error" 2 "feedback_state_high" ;
VAL_ 520 feedback_airn_gate 0 "feedback_state_low" 1 "feedback_state_error" 2 "feedback_state_high" ;
VAL_ 520 feedback_airp_gate 0 "feedback_state_low" 1 "feedback_state_error" 2 "feedback_state_high" ;
VAL_ 520 feedback_airp_status 0 "feedback_state_low" 1 "feedback_state_error" 2 "feedback_state_high" ;
VAL_ 520 feedback_airn_status 0 "feedback_state_low" 1 "feedback_state_error" 2 "feedback_state_high" ;
VAL_ 520 feedback_ts_over_60v_status 0 "feedback_state_low" 1 "feedback_state_error" 2 "feedback_state_high" ;
VAL_ 520 feedback_tsal_green 0 "feedback_state_low" 1 "feedback_state_error" 2 "feedback_state_high" ;
VAL_ 520 feedback_ext_latched 0 "feedback_state_low" 1 "feedback_state_error" 2 "feedback_state_high" ;
VAL_ 520 feedback_bms_cockpit 0 "feedback_state_low" 1 "feedback_state_error" 2 "feedback_state_high" ;
VAL_ 520 feedback_tsal_green_fault_latched 0 "feedback_state_low" 1 "feedback_state_error" 2 "feedback_state_high" ;
VAL_ 520 feedback_imd_cockpit 0 "feedback_state_low" 1 "feedback_state_error" 2 "feedback_state_high" ;
VAL_ 520 feedback_implausibility_detected 0 "feedback_state_low" 1 "feedback_state_error" 2 "feedback_state_high" ;
VAL_ 552 imd_status 0 "sc" 1 "normal" 2 "under_voltage" 3 "start_measure" 4 "device_error" 5 "earth_fault" ;
VAL_ 560 status 0 "init" 1 "idle" 2 "airn_close" 3 "precharge" 4 "airp_close" 5 "ts_on" 6 "fatal_error" ;
VAL_ 40 hv_status_set 0 "off" 1 "on" ;
VAL_ 48 hv_status_set 0 "off" 1 "on" ;
VAL_ 1544 balancing_status 0 "off" 1 "on" ;
VAL_ 1544 cellboard_id 0 "cellboard_0" 1 "cellboard_1" 2 "cellboard_2" 3 "cellboard_3" 4 "cellboard_4" 5 "cellboard_5" ;
VAL_ 1032 set_balancing_status 0 "off" 1 "on" ;
VAL_ 1040 set_balancing_status 0 "off" 1 "on" ;
VAL_ 568 status 0 "init" 1 "idle" 2 "tson" 3 "run" 4 "flashing" 5 "error" ;
VAL_ 1568 status 0 "off" 1 "on" ;
VAL_ 1576 status 0 "weak" 1 "normal" 2 "aggressive" ;
VAL_ 1048 status 0 "weak" 1 "normal" 2 "aggressive" ;
VAL_ 1584 status 0 "off" 1 "auto" 2 "manual" ;
VAL_ 1592 status 0 "off" 1 "auto" 2 "manual" ;
VAL_ 1056 status 0 "off" 1 "auto" 2 "manual" ;
VAL_ 1064 status 0 "off" 1 "auto" 2 "manual" ;
VAL_ 624 status 0 "off" 1 "on" ;
VAL_ 80 status 0 "off" 1 "on" ;
VAL_ 1600 status 0 "off" 1 "on" ;
VAL_ 1072 status 0 "off" 1 "on" ;
VAL_ 632 connected 0 "off" 1 "on" ;
VAL_ 1608 status 0 "none" 1 "check" 2 "idle" 3 "precharge" 4 "ready" 5 "charge" 6 "charge_done" 7 "balancing" 8 "error" ;
VAL_ 1608 fans_override 0 "off" 1 "on" ;
VAL_ 1080 status 0 "none" 1 "check" 2 "idle" 3 "precharge" 4 "ready" 5 "charge" 6 "charge_done" 7 "balancing" 8 "error" ;
VAL_ 1080 fans_override 0 "off" 1 "on" ;
VAL_ 640 status 0 "init" 1 "enable_inv_updates" 2 "check_inv_settings" 3 "idle" 4 "start_ts_precharge" 5 "wait_ts_precharge" 6 "wait_driver" 7 "enable_inv_drive" 8 "drive" 9 "disable_inv_drive" 10 "start_ts_discharge" 11 "re_enable_inverter_drive" 12 "wait_ts_discharge" 13 "fatal_error" ;
VAL_ 88 status 0 "idle" 1 "ready" 2 "drive" ;
VAL_ 1088 rr 0 "disabled" 1 "rfe_on" 2 "frg_on" 3 "enabled" ;
VAL_ 1088 rl 0 "disabled" 1 "rfe_on" 2 "frg_on" 3 "enabled" ;
VAL_ 672 reg_state 0 "off" 1 "on" ;
VAL_ 672 tv_state 0 "off" 1 "on" ;
VAL_ 672 sc_state 0 "off" 1 "on" ;
VAL_ 96 reg_state 0 "off" 1 "on" ;
VAL_ 96 tv_state 0 "off" 1 "on" ;
VAL_ 96 sc_state 0 "off" 1 "on" ;
VAL_ 1616 status 0 "off" 1 "on" ;
VAL_ 1096 status 0 "off" 1 "on" ;
VAL_ 688 reg_state 0 "off" 1 "on" ;
VAL_ 688 tv_state 0 "off" 1 "on" ;
VAL_ 688 sc_state 0 "off" 1 "on" ;
VAL_ 1752 status 0 "off" 1 "on" ;
VAL_ 1104 status 0 "off" 1 "on" ;
VAL_ 1112 status 0 "off" 1 "on" ;
VAL_ 1792 device_id 0 "hv_mainboard" 1 "hv_cellboard" 2 "lv" 3 "ecu" 4 "tlm" 5 "traction_control" 6 "steeering_wheel" 7 "handcart" 8 "acquisinator" ;
VAL_ 1800 device_id 0 "hv_mainboard" 1 "hv_cellboard" 2 "lv" 3 "ecu" 4 "tlm" 5 "traction_control" 6 "steeering_wheel" 7 "handcart" 8 "acquisinator" ;
VAL_ 1808 device_id 0 "hv_mainboard" 1 "hv_cellboard" 2 "lv" 3 "ecu" 4 "tlm" 5 "traction_control" 6 "steeering_wheel" 7 "handcart" 8 "acquisinator" ;
VAL_ 1824 device_id 0 "hv_mainboard" 1 "hv_cellboard" 2 "lv" 3 "ecu" 4 "tlm" 5 "traction_control" 6 "steeering_wheel" 7 "handcart" 8 "acquisinator" ;
